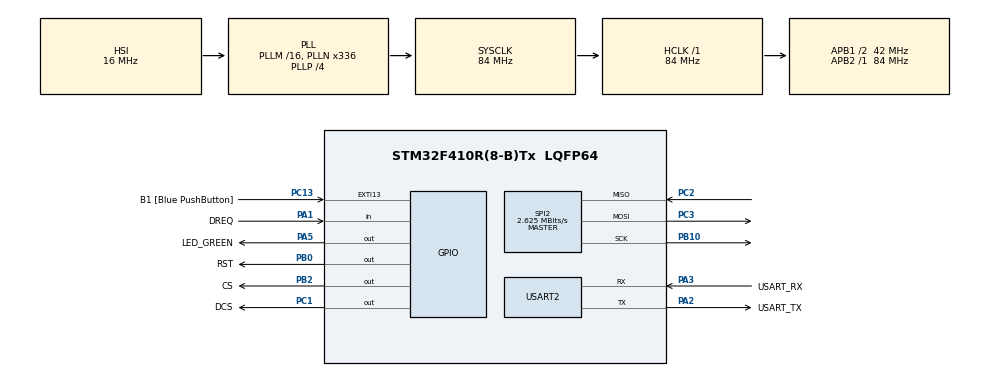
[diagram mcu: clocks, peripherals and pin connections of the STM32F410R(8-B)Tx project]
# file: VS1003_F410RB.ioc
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Mcu.Family=STM32F4
Mcu.Name=STM32F410R(8-B)Tx
Mcu.Package=LQFP64
NVIC.PriorityGroup=NVIC_PRIORITYGROUP_0
PA1.GPIO_Label=DREQ
PA1.Signal=GPIO_Input
PA13.GPIO_Label=TMS
PA13.Mode=Serial_Wire
PA13.Signal=SYS_JTMS-SWDIO
PA14.GPIO_Label=TCK
PA14.Mode=Serial_Wire
PA14.Signal=SYS_JTCK-SWCLK
PA2.GPIO_Label=USART_TX
PA2.Mode=Asynchronous
PA2.Signal=USART2_TX
PA3.GPIO_Label=USART_RX
PA3.Mode=Asynchronous
PA3.Signal=USART2_RX
PA5.GPIO_Label=LED_GREEN
PA5.Signal=GPIO_Output
PB0.GPIO_Label=RST
PB0.Signal=GPIO_Output
PB10.Mode=Full_Duplex_Master
PB10.Signal=SPI2_SCK
PB2.GPIO_Label=CS
PB2.Signal=GPIO_Output
PB3.GPIO_Label=SWO
PB3.Signal=SYS_JTDO-SWO
PC1.GPIO_Label=DCS
PC1.Signal=GPIO_Output
PC13-ANTI_TAMP.GPIO_Label=B1 [Blue PushButton]
PC13-ANTI_TAMP.GPIO_ModeDefaultEXTI=GPIO_MODE_IT_FALLING
PC13-ANTI_TAMP.Signal=GPXTI13
PC14-OSC32_IN.Mode=LSE-External-Oscillator
PC14-OSC32_IN.Signal=RCC_OSC32_IN
PC15-OSC32_OUT.Mode=LSE-External-Oscillator
PC15-OSC32_OUT.Signal=RCC_OSC32_OUT
PC2.Mode=Full_Duplex_Master
PC2.Signal=SPI2_MISO
PC3.Mode=Full_Duplex_Master
PC3.Signal=SPI2_MOSI
PH0\ -\ OSC_IN.Mode=HSE-External-Clock-Source
PH0\ -\ OSC_IN.Signal=RCC_OSC_IN
PH1\ -\ OSC_OUT.Mode=HSE-External-Clock-Source
PH1\ -\ OSC_OUT.Signal=RCC_OSC_OUT
ProjectManager.HeapSize=0x200
ProjectManager.StackSize=0x400
ProjectManager.TargetToolchain=STM32CubeIDE
RCC.48MHZClocksFreq_Value=84000000
RCC.AHBFreq_Value=84000000
RCC.APB1CLKDivider=RCC_HCLK_DIV2
RCC.APB1Freq_Value=42000000
RCC.APB1TimFreq_Value=84000000
RCC.APB2Freq_Value=84000000
RCC.APB2TimFreq_Value=84000000
RCC.CortexFreq_Value=84000000
RCC.FLatency-AdvancedSettings=FLASH_LATENCY_2
RCC.HCLKFreq_Value=84000000
RCC.HSE_VALUE=8000000
RCC.HSI_VALUE=16000000
RCC.PLLN=336
RCC.PLLP=RCC_PLLP_DIV4
RCC.SYSCLKFreq_VALUE=84000000
RCC.SYSCLKSource=RCC_SYSCLKSOURCE_PLLCLK
RCC.VCOOutputFreq_Value=336000000
SPI2.BaudRatePrescaler=SPI_BAUDRATEPRESCALER_16
SPI2.CalculateBaudRate=2.625 MBits/s
SPI2.Direction=SPI_DIRECTION_2LINES
SPI2.Mode=SPI_MODE_MASTER
SPI2.VirtualType=VM_MASTER
USART2.VirtualMode=VM_ASYNC
board=NUCLEO-F410RB

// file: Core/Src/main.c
/* USER CODE BEGIN Header */
/**
 ******************************************************************************
 * @file           : main.c
 * @brief          : Main program body
 ******************************************************************************
 * @attention
 *
 * Copyright (c) 2024 STMicroelectronics.
 * All rights reserved.
 *
 * This software is licensed under terms that can be found in the LICENSE file
 * in the root directory of this software component.
 * If no LICENSE file comes with this software, it is provided AS-IS.
 *
 ******************************************************************************
 */
/* USER CODE END Header */
#include <vs1003.h>
#include "main.h"

SPI_HandleTypeDef hspi2;

UART_HandleTypeDef huart2;

void SystemClock_Config(void);
static void MX_GPIO_Init(void);
static void MX_USART2_UART_Init(void);
static void MX_SPI2_Init(void);

/* USER CODE BEGIN 0 */
unsigned char HelloMP3[] = { 0xFF, 0xF2, 0x40, 0xC0, 0x19, 0xB7, 0x00, 0x14,
		0x02, 0xE6, 0x5C, /* ..@.......\ */
		0x01, 0x92, 0x68, 0x01, 0xF1, 0x5E, 0x03, 0x08, 0xF0, 0x24, 0x80, /* ..h..^...$. */
		0x05, 0x9E, 0x20, 0xC6, 0xFC, 0x12, 0x32, 0x5C, 0xBF, 0xF9, 0xB9, /* .. ...2\... */
		0x20, 0x4A, 0x7F, 0x85, 0xEC, 0x4C, 0xCD, 0xC7, 0x27, 0xFE, 0x5C, /*  J...L..'.\ */
		0x34, 0x25, 0xCB, 0xE6, 0xFF, 0xFF, 0x8E, 0x42, 0xE1, 0xA0, 0x5E, /* 4%.....B..^ */
		0xCA, 0x6E, 0x30, 0x9F, 0xFF, 0xF8, 0xC2, 0x12, 0x84, 0xB9, 0x7C, /* .n0.......| */
		0xDC, 0x61, 0x09, 0x4A, 0x7F, 0xFF, 0xFF, 0xF9, 0x7D, 0x32, 0x51, /* .a.J....}2Q */
		0x09, 0x7C, 0xE1, 0xA5, 0x6E, 0xB4, 0xFF, 0xFF, 0xFF, 0xFF, 0xD3, /* .|..n...... */
		0x34, 0x41, 0x91, 0xF0, 0x11, 0x8F, 0x00, 0x0F, 0x81, 0x9C, 0x10, /* 4A......... */
		0xEE, 0x59, 0xCE, 0x56, 0x67, 0xFF, 0xF2, 0x42, 0xC0, 0xEC, 0x53, /* .Y.Vg..B..S */
		0x09, 0x15, 0xF9, 0xAA, 0xA8, 0x0D, 0xD9, 0x40, 0x00, 0xCA, 0x34, /* .......@..4 */
		0x53, 0xD9, 0x18, 0xAB, 0x7D, 0xF7, 0x89, 0x3F, 0x11, 0x38, 0x94, /* S...}..?.8. */
		0x82, 0x59, 0x93, 0x20, 0x6A, 0x0C, 0xEE, 0x8E, 0x58, 0xFA, 0x38, /* .Y. j...X.8 */
		0x82, 0xCA, 0xF0, 0x58, 0xBB, 0xDA, 0x0C, 0x50, 0x56, 0x1F, 0xBB, /* ...X...PV.. */
		0x18, 0x5D, 0x8B, 0x9F, 0xDA, 0x71, 0x4F, 0xFF, 0xBD, 0xFE, 0xEF, /* .]...qO.... */
		0x69, 0x36, 0x86, 0x3C, 0x50, 0xBB, 0x0A, 0x07, 0x89, 0x54, 0xF0, /* i6.<P....T. */
		0x88, 0x9F, 0x90, 0x95, 0x30, 0x94, 0x2E, 0x7E, 0xF0, 0x64, 0x96, /* ....0..~.d. */
		0x79, 0x08, 0x3E, 0x20, 0x97, 0x28, 0x34, 0x9C, 0x09, 0x7F, 0xD2, /* y.> .(4.... */
		0xC0, 0x01, 0x75, 0xF8, 0x05, 0x6B, 0x5F, 0x41, 0x17, 0x0B, 0xE7, /* ..u..k_A... */
		0xFF, 0xF2, 0x40, 0xC0, 0x61, 0xE5, 0x0B, 0x16, 0x09, 0xC6, 0xC5, /* ..@.a...... */
		0x74, 0x7B, 0xCC, 0x94, 0x7A, 0xF7, 0x80, 0x76, 0xB2, 0xD2, 0xF8, /* t{..z..v... */
		0x39, 0x06, 0x38, 0xFD, 0x71, 0xC5, 0xDE, 0x3A, 0x38, 0xBF, 0xD5, /* 9.8.q..:8.. */
		0xF7, 0x12, 0x37, 0xCB, 0xF5, 0x63, 0x0C, 0x9B, 0xCE, 0x77, 0x25, /* ..7..c...w% */
		0xED, 0xFB, 0x3D, 0x6B, 0x35, 0xF9, 0x6D, 0xD7, 0xF9, 0x2C, 0xD1, /* ..=k5.m..,. */
		0x97, 0x15, 0x87, 0x93, 0xA4, 0x49, 0x4A, 0x18, 0x16, 0x07, 0xA1, /* .....IJ.... */
		0x60, 0xF7, 0x52, 0x94, 0xDB, 0x02, 0x16, 0x70, 0xB2, 0xD8, 0x80, /* `.R....p... */
		0x30, 0xC2, 0x94, 0x40, 0x81, 0x74, 0x5A, 0x19, 0x7A, 0x80, 0x60, /* 0..@.tZ.z.` */
		0x41, 0x21, 0x46, 0x95, 0xD5, 0xC4, 0x40, 0xD2, 0x01, 0xC0, 0x01, /* A!F...@.... */
		0xDA, 0xD9, 0xA0, 0xB1, 0x01, 0xFF, 0xF2, 0x42, 0xC0, 0x82, 0x10, /* .......B... */
		0x0B, 0x12, 0xF9, 0x9E, 0xC9, 0x7E, 0x7A, 0xC6, 0x95, 0x55, 0x09, /* .....~z..U. */
		0x8B, 0x19, 0x5E, 0x8B, 0x26, 0xCA, 0xEB, 0x68, 0x8A, 0x05, 0x8F, /* ..^.&..h... */
		0x36, 0xA5, 0xA5, 0x03, 0xB8, 0x9C, 0xED, 0x24, 0x51, 0x59, 0x90, /* 6......$QY. */
		0xF6, 0xC5, 0x7D, 0xB5, 0xAD, 0xAF, 0xF6, 0x3B, 0x18, 0xEF, 0x3F, /* ..}....;..? */
		0xFF, 0xFF, 0x4E, 0xDE, 0x16, 0x66, 0x0B, 0xAA, 0x33, 0x23, 0xDD, /* ..N..f..3#. */
		0x9C, 0x4E, 0x6E, 0x55, 0x22, 0x9D, 0xA2, 0x40, 0xA6, 0x36, 0x31, /* .NnU"..@.61 */
		0x69, 0xA5, 0xE1, 0xD9, 0x7F, 0xF7, 0xC6, 0xCC, 0x48, 0x00, 0x0E, /* i.......H.. */
		0x90, 0x16, 0x00, 0x0F, 0xDE, 0x6E, 0x80, 0x11, 0x0C, 0x9A, 0x4F, /* .....n....O */
		0x56, 0xDB, 0x88, 0xD3, 0xB2, 0x1C, 0x00, 0xE0, 0x2E, 0x3E, 0xAC, /* V........>. */
		0xFF, 0xF2, 0x40, 0xC0, 0x1C, 0xE5, 0x19, 0x13, 0x31, 0x4E, 0xCD, /* ..@.....1N. */
		0x9E, 0xC3, 0x06, 0x71, 0x03, 0x85, 0xE5, 0xB5, 0x6D, 0x88, 0x50, /* ...q....m.P */
		0x8E, 0x0E, 0x17, 0x3B, 0x19, 0xFB, 0x4E, 0x3B, 0x99, 0xEF, 0x4C, /* ...;..N;..L */
		0x9E, 0xF7, 0x7B, 0x31, 0x7C, 0x3C, 0x5F, 0xFF, 0xF4, 0xF8, 0xE3, /* ..{1|<_.... */
		0x92, 0x42, 0x07, 0x8E, 0x83, 0x8E, 0x0F, 0x05, 0x08, 0x91, 0xA3, /* .B......... */
		0x16, 0xE2, 0xDF, 0xB7, 0x62, 0x60, 0x48, 0x31, 0x3C, 0xFF, 0xD4, /* ....b`H1<.. */
		0x9E, 0x0C, 0x68, 0x00, 0x77, 0x54, 0xE3, 0x1E, 0x05, 0xC5, 0xF8, /* ..h.wT..... */
		0xEA, 0x8D, 0x82, 0x9D, 0x08, 0xA9, 0x06, 0x8D, 0x1E, 0x5D, 0x7C, /* .........]| */
		0x7F, 0x08, 0xC0, 0x50, 0x45, 0x42, 0xD0, 0x36, 0xF8, 0xB2, 0x4D, /* ...PEB.6..M */
		0x53, 0x0C, 0x80, 0x3B, 0x4D, 0xFF, 0xF2, 0x42, 0xC0, 0x2F, 0x3C, /* S..;M..B./< */
		0x25, 0x19, 0x29, 0xFE, 0xBC, 0x2E, 0xC4, 0xD0, 0x99, 0x4C, 0x48, /* %.)......LH */
		0xB0, 0x9C, 0x49, 0xD2, 0x1A, 0x2D, 0x02, 0xC2, 0x79, 0x69, 0x16, /* ..I..-..yi. */
		0x92, 0xA8, 0xC5, 0xAB, 0x45, 0x5A, 0x68, 0xE8, 0x75, 0x57, 0xCD, /* ....EZh.uW. */
		0xF1, 0xB9, 0xAA, 0x13, 0x88, 0xE4, 0x87, 0x42, 0x15, 0xB3, 0x58, /* .......B..X */
		0xF5, 0xA3, 0x46, 0xB1, 0xCF, 0xD3, 0x59, 0x7E, 0xBA, 0xB5, 0xA7, /* ..F...Y~... */
		0x6B, 0x0B, 0x17, 0x57, 0x6B, 0x5C, 0x4A, 0xCD, 0x53, 0x76, 0x2A, /* k..Wk\J.Sv* */
		0x1D, 0x28, 0xC5, 0x1C, 0x76, 0x5C, 0xDD, 0x0A, 0x00, 0x4B, 0xC0, /* .(..v\...K. */
		0x1B, 0xCA, 0xA8, 0xE9, 0x81, 0x5B, 0xA6, 0xDC, 0xA4, 0x59, 0x13, /* .....[...Y. */
		0xFC, 0xBA, 0x8F, 0x98, 0x79, 0x44, 0x25, 0xC9, 0x35, 0x38, 0xCA, /* ....yD%.58. */
		0xFF, 0xF2, 0x40, 0xC0, 0xB9, 0x7D, 0x1A, 0x13, 0x79, 0x6A, 0xC8, /* ..@..}..yj. */
		0x3E, 0xC4, 0x46, 0x94, 0x8D, 0x3C, 0x67, 0x85, 0xB1, 0xA8, 0x89, /* >.F..<g.... */
		0xC0, 0xF2, 0xE6, 0x2F, 0x9D, 0x7C, 0xC9, 0xB4, 0xBE, 0xCF, 0xE1, /* .../.|..... */
		0x7D, 0xFE, 0x1F, 0x03, 0x00, 0x12, 0x84, 0x72, 0x8C, 0xE7, 0xD8, /* }......r... */
		0x5E, 0xC9, 0xA9, 0x01, 0xBA, 0x9B, 0xC4, 0x10, 0x5C, 0x70, 0x2E, /* ^.......\p. */
		0x6C, 0x48, 0xE7, 0x8C, 0x15, 0x0B, 0x06, 0x01, 0xE5, 0xFF, 0xFF, /* lH......... */
		0xD4, 0x0D, 0x00, 0x0F, 0xCE, 0x58, 0x95, 0x61, 0xA8, 0x9E, 0x7B, /* .....X.a..{ */
		0x19, 0x98, 0xB0, 0xF0, 0xC6, 0x72, 0x82, 0xD5, 0x27, 0x06, 0x47, /* .....r..'.G */
		0x41, 0x22, 0x0F, 0x65, 0x93, 0xC9, 0x8A, 0x09, 0x19, 0x48, 0x1B, /* A".e.....H. */
		0xBD, 0xD6, 0x64, 0x1A, 0xAC, 0xFF, 0xF2, 0x42, 0xC0, 0xF1, 0x11, /* ..d....B... */
		0x25, 0x14, 0x22, 0x06, 0xBC, 0x0E, 0xD4, 0x4E, 0x99, 0x90, 0xA8, /* %."....N... */
		0xD8, 0xB7, 0xAD, 0x5D, 0x3E, 0xAF, 0x6E, 0xBE, 0x66, 0x83, 0xA4, /* ...]>.n.f.. */
		0xE3, 0xC2, 0xE0, 0x29, 0x43, 0x87, 0x5F, 0x4F, 0x27, 0x9C, 0x2C, /* ...)C._O'., */
		0xD0, 0x91, 0xF3, 0x87, 0x9B, 0x54, 0xED, 0xD1, 0xB4, 0xF3, 0x39, /* .....T....9 */
		0x87, 0x22, 0x06, 0x86, 0x0D, 0x71, 0xE4, 0x6F, 0x2A, 0x08, 0x04, /* ."...q.o*.. */
		0xC0, 0x03, 0x2A, 0xB1, 0xE2, 0x05, 0x4D, 0x64, 0xA1, 0x9C, 0xA6, /* ..*...Md... */
		0x0D, 0x41, 0xA6, 0xF2, 0x7A, 0xC1, 0x30, 0xC3, 0x38, 0x26, 0x09, /* .A..z.0.8&. */
		0x50, 0x08, 0xC4, 0xF6, 0x30, 0x0C, 0xA6, 0xA9, 0x17, 0x00, 0x13, /* P...0...... */
		0x0C, 0xDC, 0xC4, 0x2F, 0x28, 0xEB, 0x3F, 0xCD, 0x7A, 0x3D, 0x2F, /* .../(.?.z=/ */
		0xFF, 0xF2, 0x40, 0xC0, 0x18, 0x6F, 0x2E, 0x13, 0xA1, 0xF2, 0xBC, /* ..@..o..... */
		0x36, 0xCB, 0x4E, 0x99, 0x6E, 0xFC, 0xEE, 0xC5, 0xF0, 0xA0, 0xB7, /* 6.N.n...... */
		0x92, 0xD4, 0xEE, 0x79, 0x7C, 0x50, 0x5D, 0xE5, 0x04, 0x94, 0xA9, /* ...y|P].... */
		0x76, 0xCF, 0x6C, 0x70, 0xDD, 0x0D, 0xD4, 0xEE, 0xED, 0x98, 0xE8, /* v.lp....... */
		0xC8, 0x35, 0x36, 0x7A, 0x0C, 0x05, 0x80, 0x03, 0xBC, 0xBE, 0x91, /* .56z....... */
		0x00, 0x7C, 0xAE, 0x65, 0xB8, 0x91, 0xA3, 0x33, 0xBA, 0x68, 0x60, /* .|.e...3.h` */
		0xD4, 0x1A, 0x66, 0xF8, 0x43, 0xA0, 0x20, 0x89, 0xE7, 0x80, 0xD8, /* ..f.C. .... */
		0x1E, 0x4F, 0xA0, 0x04, 0x60, 0x06, 0x0A, 0xA4, 0x91, 0x24, 0xFA, /* .O..`....$. */
		0x9F, 0x57, 0x53, 0xF4, 0x7A, 0xDB, 0x5F, 0x56, 0xE3, 0x6E, 0x0B, /* .WS.z._V.n. */
		0x8B, 0x3A, 0x1C, 0xF9, 0x5E, 0xFF, 0xF2, 0x42, 0xC0, 0xB1, 0x00, /* .:..^..B... */
		0x38, 0x14, 0x09, 0xEE, 0xB4, 0x36, 0xD3, 0x4E, 0x99, 0xA4, 0x78, /* 8....6.N..x */
		0x94, 0x73, 0xC4, 0x66, 0x30, 0xF5, 0xEA, 0xDB, 0xBA, 0x67, 0x67, /* .s.f0....gg */
		0x95, 0x6B, 0xAB, 0x68, 0x5D, 0x08, 0xA1, 0x39, 0x56, 0xAB, 0x1E, /* .k.h]..9V.. */
		0xD5, 0x03, 0xE8, 0x01, 0x70, 0x00, 0xB3, 0x93, 0x33, 0x19, 0x8C, /* ....p...3.. */
		0x61, 0x8F, 0xBB, 0x5D, 0x24, 0x12, 0x63, 0xD3, 0x4B, 0x5D, 0x91, /* a..]$.c.K]. */
		0x08, 0x43, 0x22, 0x56, 0x1A, 0xC5, 0x10, 0x21, 0x84, 0xA8, 0xEA, /* .C"V...!... */
		0x80, 0xBF, 0x16, 0x8E, 0x3D, 0x46, 0x18, 0x9C, 0x6E, 0x9A, 0x91, /* ....=F..n.. */
		0xE6, 0xC9, 0x6F, 0xD2, 0x7D, 0x27, 0xD7, 0xE9, 0x6B, 0xFF, 0x0A, /* ..o.}'..k.. */
		0x03, 0x43, 0x89, 0xD5, 0xBF, 0x52, 0x97, 0x0A, 0x25, 0x95, 0x0D, /* .C...R..%.. */
		0xFF, 0xF2, 0x40, 0xC0, 0xF5, 0xC3, 0x41, 0x13, 0x81, 0xEE, 0xA8, /* ..@...A.... */
		0x5E, 0xD3, 0x44, 0x98, 0xFC, 0xCF, 0x97, 0xF9, 0x58, 0xB5, 0x33, /* ^.D.....X.3 */
		0xB1, 0x85, 0x47, 0x86, 0xD7, 0x98, 0x01, 0x3B, 0xA3, 0x4F, 0x7E, /* ..G....;.O~ */
		0x04, 0xA6, 0xC3, 0x39, 0x21, 0x70, 0x27, 0x62, 0xB5, 0x18, 0x10, /* ...9!p'b... */
		0x09, 0x99, 0x00, 0x8B, 0x7E, 0xF2, 0xBF, 0x52, 0x18, 0x26, 0x30, /* ....~..R.&0 */
		0x1C, 0xB0, 0x01, 0x49, 0x30, 0xE0, 0xC3, 0x11, 0x46, 0x05, 0xCC, /* ...I0...F.. */
		0x49, 0x14, 0x28, 0xB2, 0xED, 0x4B, 0x57, 0x5A, 0x2F, 0xB7, 0x46, /* I.(..KWZ/.F */
		0x63, 0x34, 0xD2, 0xDA, 0x9F, 0x56, 0x32, 0xB7, 0xA2, 0x25, 0xFF, /* c4...V2..%. */
		0x94, 0x28, 0x33, 0x7F, 0x3B, 0xC4, 0x50, 0xEC, 0xB1, 0xE2, 0x26, /* .(3.;.P...& */
		0xA1, 0xB7, 0x07, 0x7F, 0xFB, 0xFF, 0xF2, 0x42, 0xC0, 0x67, 0x6A, /* .......B.gj */
		0x4C, 0x13, 0xF9, 0x6A, 0x90, 0x7E, 0xDB, 0x44, 0x94, 0x3F, 0xFF, /* L..j.~.D.?. */
		0x14, 0xD6, 0x2A, 0xFF, 0xFF, 0xC1, 0x34, 0x8C, 0x48, 0x22, 0x00, /* ..*...4.H". */
		0x06, 0x8F, 0x21, 0xFD, 0x64, 0x60, 0x04, 0x92, 0x42, 0xEA, 0x74, /* ..!.d`..B.t */
		0x32, 0x37, 0xAA, 0x5A, 0x9F, 0x67, 0x01, 0x8B, 0x3F, 0x37, 0x31, /* 27.Z.g..?71 */
		0xDD, 0x06, 0x3C, 0x01, 0x34, 0x30, 0xE0, 0x5C, 0x78, 0x78, 0xCB, /* ..<.40.\xx. */
		0xD6, 0xF1, 0x31, 0x8A, 0x69, 0x61, 0x93, 0x92, 0x42, 0xCE, 0x4B, /* ..1.ia..B.K */
		0xC5, 0x02, 0x4E, 0x73, 0xC6, 0x24, 0x30, 0xCD, 0x08, 0x66, 0xC6, /* ..Ns.$0..f. */
		0x35, 0xAB, 0xA2, 0x3D, 0x2F, 0xB3, 0xBD, 0x34, 0x87, 0x13, 0xEE, /* 5..=/..4... */
		0x71, 0x45, 0x68, 0xFA, 0xEA, 0x05, 0x84, 0x41, 0x36, 0x4C, 0x9A, /* qEh....A6L. */
		0xFF, 0xF2, 0x40, 0xC0, 0xC9, 0x92, 0x56, 0x13, 0xD0, 0x6E, 0x70, /* ..@...V..np */
		0x54, 0xD3, 0xCC, 0x28, 0x06, 0xD7, 0x0E, 0xA4, 0x1D, 0x9C, 0x9D, /* T..(....... */
		0xD9, 0xA9, 0x88, 0x7B, 0xB5, 0xA3, 0x56, 0xB7, 0x4B, 0x4B, 0x5A, /* ...{..V.KKZ */
		0x9B, 0x2C, 0xA9, 0xAD, 0x6F, 0x99, 0x6C, 0xC0, 0x4C, 0x14, 0x14, /* .,..o.l.L.. */
		0xEF, 0xB4, 0x20, 0x91, 0x5F, 0xBC, 0x81, 0x41, 0x41, 0x5D, 0xD4, /* .. ._..AA]. */
		0x20, 0xBD, 0x05, 0x1A, 0x6F, 0xE2, 0x68, 0x56, 0x41, 0x41, 0x57, /*  ...o.hVAAW */
		0xF9, 0xBF, 0x89, 0x82, 0x8E, 0xC7, 0x8F, 0x0A, 0x0A, 0x09, 0x37, /* ..........7 */
		0xF1, 0x05, 0x0A, 0x0A, 0x0A, 0x0A, 0x09, 0x05, 0x37, 0xFF, 0x10, /* ........7.. */
		0x50, 0x50, 0x53, 0x65, 0xFF, 0xFF, 0xFD, 0x75, 0xDF, 0xFF, 0xFF, /* PPSe...u... */
		0x68, 0x4F, 0xFF, 0x84, 0x70, 0xFF, 0xF2, 0x42, 0xC0, 0x27, 0x50, /* hO..p..B.'P */
		0x5F, 0x17, 0xE8, 0x82, 0x3C, 0x11, 0x58, 0x18, 0x01, 0x55, 0x48, /* _...<.X..UH */
		0xBC, 0x52, 0xFC, 0x4A, 0x4C, 0x3C, 0xD5, 0xF6, 0x11, 0x2D, 0xBF, /* .R.JL<...-. */
		0xEA, 0x03, 0x5C, 0x57, 0x29, 0xBF, 0xC3, 0x75, 0x1C, 0xE6, 0xDD, /* ..\W)..u... */
		0xBF, 0xED, 0xEF, 0xD0, 0x98, 0x77, 0x71, 0x95, 0x73, 0xFF, 0xED, /* .....wq.s.. */
		0x54, 0xBE, 0xD5, 0xEE, 0xAE, 0xC2, 0xD5, 0x0B, 0xFF, 0xF1, 0x97, /* T.......... */
		0x8A, 0xE4, 0x42, 0x09, 0x99, 0xB1, 0xEA, 0x94, 0xDC, 0x78, 0xB5, /* ..B......x. */
		0x34, 0x0F, 0xF1, 0x8F, 0xFC, 0x15, 0xF6, 0xFA, 0xB1, 0x47, 0xA9, /* 4........G. */
		0x6C, 0x67, 0x43, 0x8B, 0xF2, 0x76, 0x22, 0xED, 0xDA, 0x85, 0xBA, /* lgC..v".... */
		0x2F, 0xC7, 0xF9, 0xCF, 0xFC, 0xDB, 0x46, 0x2E, 0x50, 0x0A, 0x84, /* /.....F.P.. */
		0xFF, 0xF2, 0x40, 0xC0, 0xC6, 0x4A, 0x59, 0x28, 0x2B, 0x19, 0xE0, /* ..@..JY(+.. */
		0x01, 0x89, 0x78, 0x00, 0x52, 0x85, 0x3C, 0x8E, 0x54, 0x9A, 0x48, /* ..x.R.<.T.H */
		0x5A, 0x72, 0x32, 0x94, 0xBF, 0x43, 0x4F, 0x24, 0x53, 0x4B, 0xEC, /* Zr2..CO$SK. */
		0x4B, 0x99, 0x0E, 0x66, 0x1F, 0xFF, 0xCE, 0x7F, 0xFF, 0x3F, 0x10, /* K..f.....?. */
		0xAE, 0x82, 0x62, 0x71, 0x34, 0x18, 0x59, 0x9B, 0x51, 0xC7, 0x59, /* ..bq4.Y.Q.Y */
		0xCE, 0xEE, 0xA5, 0xFE, 0x02, 0xBB, 0x30, 0x91, 0x49, 0xD5, 0x4B, /* ......0.I.K */
		0xF3, 0xDC, 0x9A, 0xA9, 0x57, 0x8E, 0x72, 0x10, 0xC0, 0x5D, 0x60, /* ....W.r..]` */
		0x67, 0xFC, 0x7D, 0xD6, 0xBA, 0xDD, 0xB3, 0x8B, 0x5A, 0x0A, 0x4C, /* g.}.....Z.L */
		0x41, 0x4D, 0x45, 0x33, 0x2E, 0x39, 0x33, 0xAA, 0xAA, 0xAA, 0xAA, /* AME3.93.... */
		0xAA, 0xAA, 0xAA, 0xAA, 0xAA, 0x54, 0x41, 0x47, 0x48, 0x65, 0x6C, /* .....TAGHel */
		0x6C, 0x6F, 0x20, 0x20, 0x20, 0x20, 0x20, 0x20, 0x20, 0x20, 0x20, /* lo          */
		0x20, 0x20, 0x20, 0x20, 0x20, 0x20, 0x20, 0x20, 0x20, 0x20, 0x20, /*             */
		0x20, 0x20, 0x20, 0x20, 0x20, 0x50, 0x61, 0x6E, 0x75, 0x2D, 0x4B, /*      Panu-K */
		0x72, 0x69, 0x73, 0x74, 0x69, 0x61, 0x6E, 0x20, 0x50, 0x6F, 0x69, /* ristian Poi */
		0x6B, 0x73, 0x61, 0x6C, 0x6F, 0x20, 0x20, 0x20, 0x20, 0x20, 0x20, /* ksalo       */
		0x20, 0x20, 0x56, 0x53, 0x44, 0x53, 0x50, 0x20, 0x54, 0x65, 0x73, /*   VSDSP Tes */
		0x74, 0x69, 0x6E, 0x67, 0x20, 0x20, 0x20, 0x20, 0x20, 0x20, 0x20, /* ting        */
		0x20, 0x20, 0x20, 0x20, 0x20, 0x20, 0x20, 0x20, 0x20, 0x20, 0x20, /*             */
		0x20, 0x20, 0x20, 0x4D, 0x50, 0x33, 0x20, 0x48, 0x65, 0x6C, 0x6C, /*    MP3 Hell */
		0x6F, 0x2C, 0x20, 0x57, 0x6F, 0x72, 0x6C, 0x64, 0x21, 0x20, 0x20, /* o, World!   */
		0x20, 0x20, 0x20, 0x20, 0x20, 0x20, 0x20, 0x20, 0x20, 0x20, 0x20, /*             */
		0x00, /* . */
};
unsigned char bell[] = { 0x49, 0x44, 0x33, 0x04, 0x00, 0x00, 0x00, 0x00, 0x00,
		0x23, 0x54, 0x53, 0x53, 0x45, 0x00, 0x00, 0x00, 0x0F, 0x00, 0x00, 0x03,
		0x4C, 0x61, 0x76, 0x66, 0x36, 0x30, 0x2E, 0x31, 0x35, 0x2E, 0x31, 0x30,
		0x30, 0x00, 0x00, 0x00, 0x00, 0x00, 0x00, 0x00, 0x00, 0x00, 0x00, 0x00,
		0xFF, 0xFB, 0x50, 0x00, 0x00, 0x00, 0x00, 0x00, 0x00, 0x00, 0x00, 0x00,
		0x00, 0x00, 0x00, 0x00, 0x00, 0x00, 0x00, 0x00, 0x00, 0x00, 0x00, 0x00,
		0x00, 0x00, 0x00, 0x00, 0x00, 0x00, 0x00, 0x00, 0x00, 0x00, 0x00, 0x00,
		0x49, 0x6E, 0x66, 0x6F, 0x00, 0x00, 0x00, 0x0F, 0x00, 0x00, 0x00, 0x47,
		0x00, 0x00, 0x1D, 0xCB, 0x00, 0x0A, 0x0D, 0x11, 0x11, 0x15, 0x18, 0x18,
		0x1C, 0x1F, 0x23, 0x23, 0x26, 0x2A, 0x2A, 0x2D, 0x31, 0x34, 0x34, 0x38,
		0x3B, 0x3B, 0x3F, 0x42, 0x46, 0x46, 0x49, 0x4D, 0x4D, 0x50, 0x54, 0x57,
		0x57, 0x5B, 0x5E, 0x5E, 0x62, 0x65, 0x65, 0x69, 0x6C, 0x70, 0x70, 0x73,
		0x77, 0x77, 0x7A, 0x7E, 0x81, 0x81, 0x85, 0x88, 0x88, 0x8C, 0x8F, 0x93,
		0x93, 0x96, 0x9A, 0x9A, 0x9D, 0xA1, 0xA4, 0xA4, 0xA8, 0xAB, 0xAB, 0xAF,
		0xB2, 0xB2, 0xB6, 0xB9, 0xBD, 0xBD, 0xC0, 0xC4, 0xC4, 0xC7, 0xCB, 0xCE,
		0xCE, 0xD2, 0xD5, 0xD5, 0xD9, 0xDC, 0xE0, 0xE0, 0xE3, 0xE7, 0xE7, 0xEA,
		0xEE, 0xF1, 0xF1, 0xF5, 0xF8, 0xF8, 0xFC, 0xFF, 0x00, 0x00, 0x00, 0x00,
		0x4C, 0x61, 0x76, 0x63, 0x36, 0x30, 0x2E, 0x33, 0x30, 0x00, 0x00, 0x00,
		0x00, 0x00, 0x00, 0x00, 0x00, 0x00, 0x00, 0x00, 0x00, 0x24, 0x02, 0x40,
		0x00, 0x00, 0x00, 0x00, 0x00, 0x00, 0x1D, 0xCB, 0x4A, 0x53, 0xAC, 0xDB,
		0x00, 0x00, 0x00, 0x00, 0x00, 0x00, 0x00, 0x00, 0x00, 0x00, 0x00, 0x00,
		0x00, 0x00, 0x00, 0x00, 0xFF, 0xFB, 0x10, 0x64, 0x00, 0x0F, 0xF0, 0x78,
		0x00, 0x3A, 0x00, 0x23, 0x10, 0x00, 0x0E, 0x60, 0x07, 0x50, 0x00, 0x00,
		0x00, 0x01, 0x74, 0x00, 0xFA, 0x00, 0x0C, 0x60, 0x00, 0x37, 0x80, 0x5F,
		0x00, 0x10, 0x8C, 0x00, 0xEA, 0x0C, 0xD4, 0x18, 0xF9, 0x43, 0x8A, 0x73,
		0x0E, 0x65, 0xDF, 0xFE, 0x48, 0x3F, 0x90, 0xEB, 0x7F, 0xC9, 0xE7, 0xC9,
		0xC3, 0xEB, 0x38, 0xB7, 0xFF, 0xE5, 0x01, 0x07, 0x43, 0xFD, 0x36, 0x84,
		0x11, 0xEC, 0xA0, 0xCE, 0x69, 0xFF, 0xFF, 0x9A, 0x15, 0x75, 0xDA, 0xC6,
		0xD2, 0xC6, 0xAA, 0xD7, 0x4A, 0x73, 0x35, 0xBB, 0xFF, 0x38, 0x2E, 0xBA,
		0xBB, 0x7C, 0xDB, 0xDF, 0x7B, 0x51, 0x6F, 0xFF, 0x55, 0x6B, 0x2C, 0xA6,
		0xFF, 0xFB, 0x12, 0x64, 0x06, 0x8F, 0xF0, 0x64, 0x00, 0x3E, 0x80, 0x20,
		0x00, 0x00, 0x0A, 0xC0, 0x07, 0xD0, 0x04, 0x00, 0x00, 0x01, 0xD8, 0x00,
		0xF6, 0x00, 0x84, 0x49, 0x40, 0x31, 0x00, 0x5E, 0xC0, 0x00, 0x88, 0x00,
		0xBE, 0xAF, 0x5C, 0xE3, 0xD9, 0x73, 0x76, 0x7F, 0xF5, 0x7A, 0x91, 0x5E,
		0x92, 0x8B, 0x7D, 0xBD, 0xE0, 0x06, 0x18, 0x7F, 0xFF, 0xCC, 0x20, 0x48,
		0x11, 0x62, 0x1F, 0x6D, 0x55, 0xDF, 0x2B, 0x62, 0x7F, 0xFF, 0xBC, 0x7A,
		0xE4, 0x2A, 0x05, 0xF8, 0x17, 0x02, 0x11, 0x1C, 0x4B, 0x56, 0x70, 0x60,
		0x32, 0x22, 0x30, 0xF2, 0x7A, 0x61, 0x04, 0xD8, 0xC2, 0x08, 0x38, 0xF1,
		0xF1, 0xB5, 0xF4, 0xDA, 0xDF, 0xFF, 0xFF, 0xCA, 0x03, 0xFF, 0xFB, 0x10,
		0x64, 0x0F, 0x8F, 0xF0, 0xAC, 0x0C, 0x47, 0x01, 0xEC, 0x30, 0x2A, 0x09,
		0xE0, 0x57, 0xE0, 0x08, 0x40, 0x00, 0x04, 0xB0, 0x37, 0x10, 0x15, 0xB7,
		0x80, 0x20, 0x39, 0x00, 0xA0, 0x42, 0x86, 0x20, 0x00, 0x27, 0xCE, 0xF0,
		0x20, 0x23, 0x31, 0x81, 0x54, 0x98, 0x60, 0xC5, 0xDA, 0x2E, 0xD3, 0xFE,
		0x8F, 0x2D, 0x7B, 0x28, 0xEA, 0xE5, 0x71, 0x68, 0x16, 0x19, 0x83, 0x48,
		0x89, 0xF0, 0xB9, 0x17, 0x25, 0xA2, 0x7A, 0x2E, 0x2E, 0x11, 0xF4, 0x34,
		0x31, 0x04, 0x1C, 0x2C, 0xD2, 0x26, 0x8D, 0x98, 0x7D, 0x6C, 0xFF, 0xFF,
		0xF4, 0x55, 0xE7, 0x53, 0x68, 0xD4, 0x29, 0x21, 0xE4, 0x78, 0x4E, 0x29,
		0x9A, 0xED, 0x7F, 0xA4, 0xDD, 0xFF, 0xFB, 0x12, 0x64, 0x07, 0x80, 0x00,
		0xF2, 0x0C, 0xD7, 0x86, 0x60, 0xA0, 0x00, 0x0F, 0x21, 0x6A, 0xA0, 0xC5,
		0x08, 0x00, 0x02, 0x54, 0x29, 0x56, 0x1D, 0x41, 0x00, 0x00, 0x3E, 0x04,
		0x6A, 0x17, 0x96, 0x20, 0x04, 0xE4, 0x19, 0x43, 0x43, 0x40, 0xD0, 0x88,
		0x54, 0x2F, 0x12, 0x84, 0x1D, 0x83, 0xA0, 0x9A, 0x38, 0x33, 0x0F, 0xF0,
		0xEC, 0xA7, 0x2E, 0x58, 0xE5, 0xC0, 0x86, 0xCB, 0x86, 0xF9, 0x43, 0x47,
		0xA5, 0x90, 0xBF, 0xA0, 0x6E, 0x91, 0x05, 0x91, 0x0E, 0x72, 0x68, 0xA3,
		0x5F, 0x56, 0x22, 0xB3, 0x3F, 0xE8, 0x07, 0x80, 0x07, 0x39, 0x1C, 0x2C,
		0x0F, 0xA8, 0x79, 0x18, 0x5C, 0xD5, 0x4F, 0x37, 0x5A, 0xA5, 0x07, 0xE0,
		0x02, 0xB3, 0xFF, 0xFB, 0x10, 0x64, 0x02, 0x03, 0xF0, 0x78, 0x04, 0xD6,
		0xA8, 0x38, 0x10, 0x8C, 0x0D, 0x80, 0xBA, 0x38, 0x40, 0x02, 0x23, 0x02,
		0xAC, 0x4B, 0x4A, 0x01, 0x69, 0xA0, 0x80, 0x3C, 0x82, 0x62, 0x40, 0x0E,
		0xE8, 0x0C, 0x0D, 0xFC, 0x99, 0xE1, 0x42, 0xD6, 0x44, 0xB5, 0x3E, 0xFB,
		0x68, 0x00, 0x02, 0x92, 0x00, 0xCB, 0x25, 0x80, 0x8F, 0x1B, 0x48, 0x31,
		0x63, 0xB9, 0x21, 0xB1, 0x86, 0x06, 0x7D, 0x93, 0xBE, 0x77, 0x29, 0xCE,
		0x8A, 0xE7, 0xF2, 0xBE, 0x74, 0xB7, 0x95, 0x79, 0xEE, 0x74, 0xFF, 0x3A,
		0x58, 0x28, 0x4C, 0xA0, 0x28, 0x0F, 0xFD, 0xFF, 0x3C, 0xB0, 0x4C, 0xB0,
		0x4C, 0xE1, 0xC2, 0x03, 0xE0, 0x07, 0x35, 0x4E, 0xD2, 0x0D, 0xFF, 0xFB,
		0x12, 0x64, 0x03, 0x83, 0xF0, 0xA9, 0x0E, 0xD3, 0x2B, 0x49, 0x11, 0x18,
		0x0E, 0x81, 0x39, 0x70, 0x03, 0x71, 0x03, 0x02, 0x78, 0x1F, 0x6F, 0x00,
		0xB0, 0xC0, 0xA8, 0x34, 0x84, 0x28, 0x80, 0x2C, 0x98, 0x4C, 0xEC, 0x6A,
		0x44, 0x26, 0x34, 0x5C, 0x6C, 0x6E, 0x80, 0x5D, 0x46, 0xE0, 0xF4, 0xCA,
		0x41, 0xC9, 0xF6, 0x64, 0xFF, 0xE6, 0x4E, 0x4F, 0x08, 0xF1, 0x72, 0x10,
		0x9F, 0xE4, 0x2E, 0x15, 0xFF, 0xEC, 0x10, 0x2C, 0x04, 0x62, 0x6C, 0xCC,
		0x2D, 0x40, 0xE1, 0x6B, 0x30, 0x81, 0x10, 0xC8, 0xEF, 0x33, 0x7C, 0x61,
		0x17, 0x05, 0x93, 0x2F, 0x9C, 0x9C, 0x38, 0x1D, 0xE9, 0x44, 0x14, 0xA5,
		0x80, 0x00, 0x09, 0x20, 0x21, 0x43, 0x42, 0xFF, 0xFB, 0x10, 0x64, 0x03,
		0x81, 0x30, 0xAE, 0x07, 0x59, 0x21, 0x38, 0x40, 0x9A, 0x0E, 0xE0, 0xEA,
		0xE4, 0x05, 0xE5, 0x03, 0x42, 0x00, 0x17, 0x75, 0x80, 0x08, 0xC0, 0x30,
		0x3C, 0x85, 0x6A, 0x11, 0x11, 0x1C, 0x9C, 0x21, 0x08, 0x97, 0x53, 0xFD,
		0x4C, 0xA5, 0x06, 0xF2, 0x4D, 0xC8, 0xEC, 0x83, 0x4D, 0xA0, 0xC0, 0x81,
		0x50, 0x01, 0x29, 0x10, 0xF0, 0xDB, 0x57, 0x84, 0x96, 0x89, 0x1B, 0x25,
		0x90, 0x61, 0xB7, 0x23, 0x00, 0x30, 0x83, 0x03, 0x5B, 0xA9, 0x91, 0x4A,
		0x2E, 0x72, 0xAF, 0xFF, 0x68, 0x40, 0x81, 0x54, 0x03, 0x3B, 0x01, 0x1A,
		0x1D, 0x80, 0xC1, 0xEA, 0x20, 0x8F, 0xE0, 0x39, 0x02, 0x00, 0x07, 0x29,
		0x81, 0x86, 0x4F, 0xFF, 0xFB, 0x12, 0x64, 0x03, 0x8B, 0xF0, 0x8F, 0x06,
		0x55, 0xA8, 0x18, 0x38, 0x18, 0x0D, 0xA1, 0x59, 0xE0, 0x03, 0x27, 0x05,
		0x02, 0x78, 0x3F, 0x50, 0x0C, 0x18, 0x45, 0x20, 0x37, 0x83, 0xE8, 0xC0,
		0x1C, 0x24, 0x0C, 0x21, 0x94, 0x88, 0xA0, 0xC8, 0xB1, 0x5B, 0xCF, 0xD1,
		0x8B, 0x55, 0x06, 0xB9, 0x27, 0xFF, 0xE5, 0x6E, 0x39, 0x2E, 0x4C, 0x00,
		0xF1, 0xAF, 0xF0, 0xEE, 0xE3, 0x6A, 0x4C, 0x6F, 0x7B, 0x53, 0x0D, 0x62,
		0xCA, 0x05, 0xF3, 0xE0, 0x3F, 0xE3, 0x41, 0x63, 0x43, 0x52, 0x71, 0x9A,
		0xAB, 0x99, 0xE0, 0x04, 0x40, 0x5C, 0xD0, 0xB2, 0x21, 0x6F, 0x19, 0xBB,
		0x11, 0x2A, 0xB0, 0x00, 0x66, 0xAF, 0x9C, 0x63, 0xE1, 0x00, 0x72, 0x0C,
		0xFF, 0xFB, 0x10, 0x64, 0x05, 0x0F, 0x70, 0xA1, 0x08, 0xD7, 0x80, 0x2F,
		0x30, 0xA2, 0x0D, 0x40, 0xBA, 0x65, 0x03, 0x06, 0x03, 0x42, 0x40, 0x1F,
		0x6A, 0x00, 0xE0, 0xC2, 0x80, 0x36, 0x84, 0x2A, 0x80, 0x37, 0x94, 0x4D,
		0x3C, 0x9A, 0xCA, 0x42, 0x30, 0x23, 0x9F, 0x93, 0x93, 0x6D, 0x20, 0x00,
		0x02, 0xFD, 0xE1, 0x67, 0x26, 0xC1, 0xE1, 0x70, 0xB6, 0x22, 0xF1, 0x19,
		0x67, 0xA2, 0x20, 0xC2, 0x39, 0x6E, 0xED, 0x18, 0x19, 0x18, 0x3A, 0x84,
		0xA1, 0xBA, 0x9F, 0x5B, 0x84, 0x50, 0x1A, 0x31, 0x0D, 0x99, 0x12, 0xA6,
		0x07, 0x8F, 0x1A, 0xD1, 0x96, 0x45, 0x0F, 0x82, 0x51, 0x18, 0x70, 0x2B,
		0xE6, 0x08, 0x3C, 0x98, 0x23, 0x51, 0xEE, 0x45, 0xFF, 0xFB, 0x12, 0x44,
		0x06, 0x81, 0xF0, 0x74, 0x07, 0x57, 0x80, 0x38, 0x30, 0x98, 0x0F, 0x40,
		0xCA, 0xF0, 0x07, 0x26, 0x13, 0x01, 0xCC, 0x13, 0x85, 0xA0, 0x04, 0xC0,
		0x30, 0x39, 0x03, 0xAB, 0x40, 0x1C, 0x24, 0x48, 0xB9, 0x58, 0x02, 0x6B,
		0x45, 0xF8, 0x06, 0xC0, 0x93, 0x07, 0xA6, 0x00, 0xC5, 0x84, 0x13, 0x6E,
		0x54, 0x66, 0x6B, 0x82, 0x8B, 0x40, 0x02, 0x11, 0x53, 0x6A, 0xA5, 0x4E,
		0xE5, 0x3B, 0xF4, 0xF1, 0x24, 0xB3, 0x6A, 0x82, 0xE4, 0xF1, 0x1E, 0x4C,
		0x1C, 0xAE, 0x87, 0x9C, 0xFD, 0xF5, 0xD6, 0xD8, 0xDB, 0x65, 0x19, 0xA6,
		0x34, 0x64, 0xA2, 0x05, 0x91, 0x00, 0xAE, 0x7F, 0x57, 0x7F, 0x0E, 0x02,
		0x07, 0x85, 0x8F, 0x8C, 0x4A, 0xFF, 0xFB, 0x10, 0x64, 0x0B, 0x8B, 0x70,
		0x7D, 0x07, 0x56, 0x00, 0x1A, 0x40, 0x20, 0x0F, 0x00, 0xE9, 0xE0, 0x2B,
		0x6A, 0x15, 0x01, 0xA0, 0x1D, 0x5C, 0xA0, 0x65, 0x22, 0x60, 0x35, 0x83,
		0xE9, 0x94, 0x5C, 0x24, 0x4C, 0x21, 0x24, 0x99, 0xDB, 0xE7, 0x0E, 0xC1,
		0x12, 0x59, 0x43, 0x7E, 0x14, 0x85, 0x08, 0xC4, 0x8E, 0x13, 0xFE, 0x8E,
		0xFF, 0x42, 0x1C, 0x31, 0x09, 0xF0, 0xF0, 0x8F, 0x45, 0xF8, 0x17, 0x8A,
		0x04, 0xAD, 0x7B, 0x05, 0xC0, 0x04, 0xA3, 0xB8, 0x50, 0x0D, 0x83, 0x62,
		0xB0, 0xA1, 0x74, 0x93, 0xA6, 0x09, 0x2A, 0xAA, 0xA8, 0xAC, 0xB2, 0x0B,
		0xB8, 0xCC, 0x34, 0x1A, 0x99, 0x01, 0x90, 0xB8, 0x38, 0x03, 0x9C, 0xD2,
		0x35, 0xFF, 0xFB, 0x12, 0x64, 0x11, 0x01, 0xF0, 0x8E, 0x07, 0x5B, 0xA8,
		0x03, 0x48, 0x1A, 0x0F, 0x20, 0xBA, 0xB0, 0x00, 0x2F, 0x01, 0x02, 0x10,
		0x13, 0x95, 0xA0, 0x04, 0x40, 0x30, 0x3C, 0x83, 0xA9, 0xC0, 0x03, 0x60,
		0x45, 0x47, 0x6C, 0x36, 0xB4, 0x01, 0x63, 0x41, 0x40, 0x4A, 0x87, 0x42,
		0xB7, 0xF2, 0x5D, 0x3D, 0x60, 0x31, 0xA5, 0x83, 0xA2, 0xA2, 0x2B, 0xA2,
		0xB5, 0x7A, 0x4A, 0xB6, 0x01, 0x06, 0x2B, 0xC5, 0x8D, 0xC6, 0x0B, 0x00,
		0x93, 0x10, 0x2F, 0x19, 0x4F, 0x80, 0x5F, 0x86, 0xFB, 0x7A, 0x0C, 0x02,
		0xA0, 0x00, 0x39, 0xA4, 0x4C, 0x55, 0xE1, 0xDF, 0xCB, 0x40, 0xB0, 0x38,
		0x6F, 0x38, 0xCD, 0x14, 0x1E, 0x93, 0x26, 0x3E, 0xEF, 0xB0, 0xFF, 0xFB,
		0x10, 0x64, 0x13, 0x0F, 0x30, 0x72, 0x09, 0xD8, 0x00, 0x1A, 0x28, 0xA0,
		0x0E, 0x60, 0xFA, 0xB8, 0x05, 0xE3, 0x23, 0x41, 0xD0, 0x27, 0x5E, 0x00,
		0xE4, 0x42, 0x80, 0x38, 0x83, 0xE9, 0x80, 0x1C, 0x88, 0x54, 0xC0, 0x5E,
		0x0C, 0x6F, 0xF4, 0xF2, 0x7E, 0xA0, 0x44, 0x26, 0x20, 0x18, 0xE6, 0x81,
		0xA5, 0x9D, 0xF1, 0xFD, 0x04, 0x95, 0x6E, 0x4D, 0xA9, 0x60, 0xBF, 0x3B,
		0x8A, 0x45, 0x50, 0xAC, 0x9C, 0x30, 0xC9, 0xC8, 0xF1, 0xA8, 0xA8, 0x8B,
		0x0A, 0x16, 0xB0, 0xAF, 0x54, 0xC6, 0xF8, 0xD1, 0xFF, 0x83, 0x16, 0x80,
		0xAB, 0x14, 0x40, 0x00, 0x99, 0xCB, 0x25, 0x38, 0xC0, 0x94, 0x7B, 0x24,
		0xAF, 0x67, 0x58, 0xD4, 0x88, 0xD0, 0xFF, 0xFB, 0x12, 0x64, 0x18, 0x01,
		0x30, 0x71, 0x09, 0xD6, 0x80, 0x19, 0x28, 0xA8, 0x0D, 0xE1, 0xAA, 0x50,
		0x0B, 0x22, 0x15, 0x02, 0x14, 0x17, 0x75, 0xA0, 0x05, 0x80, 0x20, 0x3B,
		0x02, 0xAC, 0x90, 0x05, 0x30, 0x0C, 0x15, 0x14, 0x27, 0x57, 0x16, 0x40,
		0x05, 0x00, 0x62, 0xE4, 0xFD, 0xEA, 0x08, 0x10, 0x3E, 0x80, 0x00, 0x06,
		0x26, 0x78, 0x26, 0x22, 0x2D, 0x15, 0xDE, 0xFE, 0x1C, 0xEA, 0xF7, 0x36,
		0x55, 0xDE, 0x23, 0x31, 0x33, 0x00, 0x80, 0x24, 0xC2, 0x6C, 0x80, 0x59,
		0x7C, 0x67, 0x0D, 0x50, 0x4B, 0x06, 0x28, 0xC8, 0x33, 0xA5, 0x13, 0x93,
		0x96, 0x62, 0xCF, 0x74, 0x75, 0x9A, 0x17, 0x01, 0x34, 0x22, 0x2F, 0x80,
		0xBE, 0x69, 0x3D, 0xFF, 0xFB, 0x10, 0x64, 0x1C, 0x81, 0x30, 0x89, 0x05,
		0xDA, 0xC8, 0x09, 0xC0, 0x98, 0x0E, 0xE1, 0x1A, 0x10, 0x03, 0x6D, 0x15,
		0x01, 0xE4, 0x17, 0x5C, 0x00, 0x33, 0x22, 0x00, 0x35, 0x83, 0xEB, 0x60,
		0x03, 0xBC, 0x14, 0xB4, 0xD3, 0x4C, 0xBA, 0xE5, 0x10, 0x8B, 0x16, 0x1C,
		0xD9, 0x80, 0xB1, 0x5D, 0xC3, 0x06, 0x56, 0xD4, 0x42, 0x35, 0x8E, 0x40,
		0x3A, 0xF8, 0x38, 0x46, 0x30, 0x4E, 0x88, 0x07, 0xAE, 0x6A, 0x3E, 0xA2,
		0x13, 0xAE, 0x1B, 0xB4, 0xDB, 0x2A, 0xD0, 0x16, 0x57, 0x68, 0x49, 0x4A,
		0xBC, 0x33, 0xAD, 0xCB, 0x9F, 0x6D, 0xD2, 0x44, 0xFD, 0x55, 0x4A, 0x10,
		0x42, 0xAF, 0x0C, 0xEB, 0x21, 0x0E, 0x84, 0x7C, 0x62, 0x19, 0xFE, 0xFF,
		0xFB, 0x12, 0x44, 0x20, 0x0F, 0x30, 0x79, 0x09, 0x56, 0x00, 0x38, 0x10,
		0xA8, 0x0F, 0xA1, 0x2B, 0x74, 0x09, 0x82, 0x15, 0x01, 0xA0, 0x25, 0x56,
		0x00, 0x60, 0xA2, 0xA0, 0x35, 0x04, 0xAA, 0xC0, 0x0C, 0x14, 0x54, 0x36,
		0x7B, 0x44, 0x4E, 0x0B, 0x1F, 0xE4, 0x7A, 0x40, 0x10, 0x01, 0xE4, 0x1D,
		0x00, 0xE0, 0x61, 0x1E, 0x38, 0x18, 0x54, 0x87, 0xDB, 0xD0, 0x29, 0x3E,
		0x24, 0x03, 0x66, 0xE4, 0x37, 0x8C, 0x15, 0xFE, 0x1B, 0xEC, 0xE8, 0x30,
		0x44, 0x05, 0x04, 0xA3, 0x86, 0x17, 0x69, 0x26, 0x1B, 0x07, 0xAF, 0xC0,
		0xFD, 0xF5, 0x43, 0x60, 0x07, 0x70, 0xED, 0xE7, 0x55, 0x36, 0x4C, 0xD6,
		0x7D, 0x43, 0x97, 0x47, 0x45, 0xD9, 0xC8, 0x74, 0xFF, 0xFB, 0x10, 0x64,
		0x26, 0x0B, 0xF0, 0x7A, 0x05, 0xD5, 0x80, 0x12, 0xC8, 0x90, 0x0E, 0xA0,
		0xBA, 0x95, 0x00, 0xD1, 0x05, 0x01, 0xA4, 0x27, 0x5E, 0xA0, 0x60, 0xA2,
		0xA0, 0x39, 0x82, 0xA9, 0x40, 0x06, 0x60, 0x48, 0x8F, 0x50, 0xDD, 0x80,
		0x20, 0x0B, 0x9D, 0x4C, 0xA0, 0x5D, 0x1A, 0xD9, 0x5D, 0x04, 0x37, 0x70,
		0x4A, 0xDC, 0xFE, 0x16, 0x1A, 0x2B, 0x04, 0xF7, 0x04, 0xAC, 0x10, 0x25,
		0xC4, 0x17, 0x0E, 0x7F, 0x1F, 0x96, 0xFE, 0x58, 0x50, 0x00, 0x60, 0x01,
		0x23, 0xF7, 0x92, 0xF4, 0x34, 0x0A, 0xBF, 0x81, 0x4D, 0x87, 0x04, 0x1A,
		0x11, 0x76, 0xCF, 0x5A, 0x00, 0x00, 0x01, 0xCE, 0x88, 0x68, 0x6B, 0x10,
		0xE0, 0x73, 0x0B, 0xC2, 0xFF, 0xFB, 0x12, 0x64, 0x2B, 0x03, 0x30, 0x91,
		0x06, 0xD6, 0xA8, 0x38, 0x30, 0xA8, 0x0F, 0x00, 0xFB, 0x14, 0x00, 0x4C,
		0x01, 0x02, 0x94, 0x47, 0x4E, 0x01, 0x65, 0x42, 0x80, 0x3C, 0x84, 0x6A,
		0x50, 0x07, 0x8C, 0x1C, 0x80, 0x1C, 0x2B, 0xD6, 0x19, 0xF8, 0x5F, 0xF8,
		0x6B, 0x5A, 0xBE, 0xDD, 0x29, 0x49, 0x6C, 0xA5, 0x7E, 0x8C, 0xD2, 0x0F,
		0xC6, 0x3F, 0x57, 0x92, 0x0B, 0x8A, 0x3C, 0xC5, 0x20, 0x63, 0x40, 0x05,
		0x8C, 0xDF, 0x40, 0x2B, 0x0B, 0x84, 0x77, 0xE0, 0xCF, 0x21, 0xCD, 0xE0,
		0x73, 0x20, 0xC9, 0xC1, 0x34, 0x48, 0xFA, 0xDC, 0xCE, 0xBA, 0x67, 0x60,
		0x07, 0x36, 0xEF, 0x13, 0x1D, 0x0B, 0x25, 0x10, 0xE7, 0x54, 0x28, 0x92,
		0xC6, 0xFF, 0xFB, 0x10, 0x64, 0x2B, 0x03, 0xB0, 0xCD, 0x16, 0x5E, 0x68,
		0x09, 0x28, 0x3C, 0x0F, 0x61, 0x2A, 0x30, 0x03, 0x23, 0x14, 0x02, 0x1C,
		0x25, 0x3A, 0x00, 0x72, 0x22, 0xA0, 0x32, 0x83, 0xE8, 0x14, 0x09, 0x24,
		0x5C, 0x81, 0xBC, 0x8F, 0x5F, 0x40, 0x34, 0x8B, 0xC6, 0x4C, 0x04, 0xFA,
		0x9E, 0x02, 0x58, 0x9A, 0x83, 0x39, 0xDB, 0xD4, 0x04, 0xF9, 0xC4, 0x2D,
		0x8E, 0x15, 0xB3, 0x81, 0x15, 0x25, 0x3A, 0xB8, 0x3D, 0x46, 0x46, 0x2F,
		0x82, 0x9D, 0xCB, 0x78, 0x42, 0xD1, 0x9D, 0x52, 0x19, 0x2B, 0x49, 0xB2,
		0xF5, 0xEB, 0xD7, 0xEF, 0xFF, 0x2D, 0x2A, 0x02, 0x60, 0x04, 0x6F, 0x26,
		0xF1, 0x5A, 0x87, 0xBE, 0xE5, 0x07, 0x5D, 0x8B, 0xC1, 0xFF, 0xFB, 0x12,
		0x64, 0x29, 0x83, 0xF0, 0x95, 0x09, 0xD5, 0xA8, 0x38, 0x28, 0xA8, 0x0F,
		0x41, 0x1A, 0x20, 0x2B, 0x03, 0x22, 0x02, 0x68, 0x37, 0x56, 0xA0, 0xE0,
		0x42, 0xA0, 0x3C, 0x84, 0xA7, 0x81, 0x0D, 0x3C, 0x8C, 0x7C, 0x83, 0xF4,
		0x76, 0xE4, 0x5E, 0xA5, 0x8B, 0x9D, 0x75, 0xA9, 0xD0, 0x94, 0x59, 0x08,
		0x32, 0xFB, 0xFF, 0xA1, 0x9D, 0xF6, 0xF6, 0xD4, 0x24, 0x13, 0xE6, 0x66,
		0x4B, 0x8B, 0x6F, 0x32, 0x04, 0x7F, 0x92, 0xE4, 0xDB, 0xCE, 0xD9, 0xA7,
		0x38, 0x80, 0xF0, 0xEA, 0x59, 0x7F, 0x81, 0x07, 0x4F, 0x7D, 0x46, 0xC0,
		0x07, 0x40, 0xF2, 0x0B, 0x04, 0xFE, 0x08, 0xD5, 0x27, 0x36, 0xBC, 0x7A,
		0xB6, 0xF4, 0x7F, 0x21, 0x49, 0x74, 0xFF, 0xFB, 0x10, 0x64, 0x29, 0x83,
		0xF0, 0x89, 0x09, 0xD4, 0xA8, 0x18, 0x28, 0xA8, 0x0F, 0xA1, 0x2A, 0x00,
		0x07, 0x23, 0x14, 0x01, 0xE8, 0x23, 0x54, 0xA0, 0xE0, 0x62, 0xA0, 0x3A,
		0x84, 0xA8, 0x40, 0x1C, 0x98, 0x54, 0x2B, 0xBB, 0x3A, 0x54, 0x73, 0x17,
		0x0D, 0x53, 0xFF, 0xF2, 0x0E, 0xEC, 0xEB, 0x94, 0x85, 0xA0, 0x9A, 0xE0,
		0x80, 0xC0, 0x56, 0xB3, 0xCB, 0xC9, 0xBF, 0x4E, 0x00, 0x56, 0x40, 0xA3,
		0x70, 0xDC, 0x9B, 0xC6, 0x8F, 0x2C, 0xE7, 0x67, 0xF5, 0x2A, 0x74, 0xA9,
		0x46, 0x4E, 0xA7, 0x8D, 0xC0, 0xF0, 0xF7, 0xE1, 0x80, 0x30, 0x00, 0x04,
		0x45, 0xF0, 0x09, 0xA4, 0xE1, 0x74, 0xF7, 0x38, 0x5D, 0xA7, 0xF4, 0xB3,
		0xAE, 0x6B, 0xFF, 0xFB, 0x12, 0x64, 0x2C, 0x03, 0xB0, 0x81, 0x09, 0xD6,
		0x28, 0xF8, 0x11, 0x18, 0x0E, 0x41, 0x2A, 0x20, 0x23, 0x05, 0x30, 0x01,
		0xE8, 0x17, 0x4E, 0x00, 0x65, 0x22, 0x80, 0x36, 0x02, 0xE9, 0x14, 0x03,
		0x60, 0x4C, 0x96, 0xF0, 0xD7, 0x76, 0x01, 0x51, 0xA5, 0x2D, 0xA7, 0x9D,
		0x04, 0xFA, 0x50, 0x17, 0xAF, 0xB0, 0xAF, 0x0E, 0x20, 0x89, 0x08, 0xDE,
		0x04, 0x38, 0xED, 0x48, 0xBB, 0x90, 0x21, 0x4D, 0x02, 0xA1, 0x7C, 0xFF,
		0xED, 0x80, 0x00, 0x00, 0x05, 0x1F, 0x1C, 0x2D, 0x63, 0x19, 0xBC, 0x0D,
		0x87, 0x0F, 0x65, 0x3B, 0x9D, 0xD8, 0x08, 0x40, 0x00, 0xBD, 0xDC, 0x03,
		0x80, 0xB3, 0xF7, 0xF4, 0xF4, 0xF5, 0x4D, 0xE4, 0x87, 0x8E, 0xB0, 0xFF,
		0xFB, 0x10, 0x64, 0x30, 0x83, 0xB0, 0x53, 0x09, 0x54, 0x00, 0x18, 0x28,
		0xA8, 0x0E, 0xC1, 0x3A, 0x25, 0x01, 0x33, 0x11, 0x02, 0x34, 0x37, 0x54,
		0xA0, 0xBC, 0x42, 0xE0, 0x3B, 0x84, 0xA8, 0x01, 0x09, 0x88, 0xC4, 0xA3,
		0xBF, 0xA6, 0xA2, 0x80, 0xC4, 0x2D, 0xA8, 0x00, 0x52, 0x22, 0x1D, 0x46,
		0x78, 0xAC, 0x52, 0x8E, 0x02, 0x01, 0x8A, 0x27, 0x40, 0x04, 0xB2, 0xE1,
		0x08, 0x1F, 0x23, 0x09, 0xDF, 0xE1, 0x9A, 0xDF, 0xA2, 0x3A, 0xC4, 0xC4,
		0x6D, 0x85, 0x13, 0x05, 0xDC, 0x55, 0xB1, 0x2C, 0x4E, 0x82, 0x2F, 0x12,
		0xF5, 0x45, 0xEF, 0x40, 0xCA, 0xB4, 0x1D, 0xD4, 0x02, 0x8C, 0xF6, 0x40,
		0x51, 0x11, 0x02, 0x49, 0x04, 0x8C, 0x41, 0xFF, 0xFB, 0x12, 0x64, 0x35,
		0x83, 0x30, 0xAF, 0x06, 0xDE, 0xE8, 0x08, 0x10, 0x8C, 0x0C, 0x40, 0x9A,
		0x85, 0x00, 0xAF, 0x11, 0x81, 0x24, 0x25, 0x52, 0x00, 0x60, 0x42, 0xA0,
		0x3D, 0x84, 0xAA, 0xD0, 0x06, 0x0C, 0x55, 0x03, 0xC0, 0x33, 0x7C, 0x3B,
		0x27, 0x62, 0xF6, 0xAA, 0x81, 0x61, 0xD2, 0x17, 0xC8, 0x80, 0x35, 0xFC,
		0x51, 0x91, 0x49, 0x4B, 0x02, 0x07, 0xE4, 0x7A, 0x7C, 0x1E, 0xC1, 0xD8,
		0x08, 0x91, 0xA1, 0x16, 0x7C, 0x5A, 0x7A, 0xBE, 0xD5, 0x6E, 0x5E, 0xBC,
		0xAB, 0x11, 0x11, 0x2B, 0xBC, 0xB1, 0x2B, 0x64, 0x2B, 0xAA, 0xD1, 0x03,
		0x65, 0x76, 0x72, 0x9D, 0x40, 0x70, 0x2F, 0x50, 0x01, 0x49, 0x97, 0x60,
		0x08, 0x1E, 0x69, 0xC4, 0xFF, 0xFB, 0x10, 0x64, 0x3A, 0x83, 0x30, 0x7A,
		0x09, 0x54, 0x28, 0x18, 0x18, 0xA8, 0x0E, 0xE0, 0xAA, 0xE4, 0x00, 0x29,
		0x01, 0x01, 0x6C, 0x25, 0x4C, 0x00, 0x60, 0xA2, 0xA0, 0x3B, 0x02, 0x6A,
		0x90, 0x00, 0xA4, 0x05, 0x45, 0x61, 0x34, 0x8A, 0xE3, 0x8C, 0xE6, 0xE4,
		0xA6, 0xC9, 0x9B, 0x10, 0x6B, 0xAF, 0x7E, 0x8A, 0x9E, 0xA8, 0xCF, 0xF6,
		0x71, 0x98, 0x75, 0xB4, 0x08, 0xF8, 0xFA, 0x9F, 0xE0, 0xB0, 0x98, 0xC0,
		0xC6, 0x1A, 0xFD, 0x50, 0x1E, 0x38, 0x71, 0x89, 0x04, 0x3F, 0xF5, 0xEC,
		0x02, 0xFC, 0xCE, 0x88, 0xE5, 0xCC, 0x77, 0x54, 0xC1, 0x57, 0xA6, 0xDB,
		0x3B, 0x04, 0x4D, 0x44, 0x28, 0xED, 0xE0, 0x11, 0x81, 0xBA, 0xE6, 0xF1,
		0xFF, 0xFB, 0x12, 0x64, 0x40, 0x0F, 0x30, 0x82, 0x09, 0xD1, 0x00, 0x19,
		0x10, 0xA0, 0x0F, 0x61, 0x29, 0x60, 0x4A, 0xAF, 0x23, 0x02, 0x18, 0x27,
		0x4A, 0x00, 0x64, 0xA2, 0x80, 0x3C, 0x83, 0xEA, 0x90, 0x07, 0xA4, 0x44,
		0xC5, 0x86, 0x5E, 0x83, 0x8E, 0x65, 0x54, 0xF5, 0x5C, 0x4F, 0x68, 0x15,
		0x7B, 0xEB, 0x17, 0xED, 0xE4, 0x79, 0x2D, 0x08, 0x53, 0xC8, 0x8B, 0x40,
		0x0A, 0x1E, 0x26, 0xED, 0xAD, 0xF5, 0xFF, 0xCE, 0xC4, 0x2F, 0xB9, 0x4C,
		0x50, 0x03, 0x28, 0x3C, 0xD5, 0xE8, 0x38, 0x1C, 0x01, 0xB0, 0x03, 0x00,
		0x00, 0x76, 0x91, 0x87, 0xF7, 0x89, 0xBF, 0xDF, 0x67, 0x94, 0x48, 0xC9,
		0xA8, 0x47, 0xCF, 0x7E, 0x7F, 0x92, 0x80, 0xDE, 0x02, 0xFF, 0xFB, 0x10,
		0x64, 0x42, 0x8F, 0xF0, 0x81, 0x09, 0x52, 0x80, 0x38, 0x18, 0xA0, 0x0E,
		0x61, 0x29, 0xE0, 0x0B, 0x03, 0x15, 0x02, 0x14, 0x25, 0x44, 0x05, 0x60,
		0x64, 0x40, 0x3B, 0x83, 0x67, 0xC0, 0x04, 0xE0, 0x0D, 0x08, 0x06, 0x81,
		0x10, 0x18, 0xE2, 0x1D, 0x19, 0x83, 0xCC, 0x3B, 0x70, 0x45, 0xC8, 0x17,
		0x46, 0x04, 0x47, 0xDB, 0x05, 0x81, 0xD5, 0x9C, 0x31, 0xB3, 0x96, 0xF7,
		0x81, 0x00, 0x71, 0x80, 0x03, 0xF2, 0xCC, 0x31, 0x03, 0x64, 0x1B, 0x89,
		0x52, 0x01, 0x6A, 0x69, 0x98, 0xD1, 0x23, 0xC0, 0x0B, 0x34, 0x81, 0xFE,
		0x30, 0xD8, 0xC4, 0x92, 0x5F, 0x08, 0xDE, 0x78, 0xBC, 0x78, 0xBB, 0x9D,
		0x39, 0xFC, 0xE2, 0x77, 0x41, 0xFF, 0xFB, 0x12, 0x64, 0x45, 0x8F, 0x10,
		0x9A, 0x09, 0x50, 0x80, 0x39, 0x40, 0xA0, 0x0E, 0xE1, 0x29, 0xB0, 0x07,
		0x4B, 0x14, 0x01, 0x50, 0x25, 0x48, 0x00, 0x60, 0x42, 0xA0, 0x35, 0x01,
		0xAB, 0xB4, 0x00, 0x30, 0x04, 0xF0, 0x7D, 0x80, 0x8A, 0xEB, 0x50, 0x40,
		0x28, 0xCB, 0x91, 0x07, 0x9D, 0xCB, 0x9E, 0xBB, 0xBE, 0x85, 0xC8, 0x8D,
		0xE2, 0xB5, 0x80, 0xA9, 0x14, 0x39, 0xFC, 0x02, 0xD1, 0xF3, 0x4D, 0x78,
		0xFD, 0x60, 0x40, 0x00, 0x76, 0x71, 0x92, 0x78, 0x46, 0xD1, 0x58, 0x4A,
		0x89, 0x24, 0x6F, 0xFD, 0xC8, 0x43, 0xE4, 0xC3, 0x11, 0xD2, 0xC9, 0x06,
		0x69, 0x0A, 0x90, 0x6E, 0x61, 0x50, 0xEA, 0xF8, 0xFF, 0x49, 0x2B, 0x2C,
		0x00, 0x58, 0xFF, 0xFB, 0x10, 0x64, 0x4B, 0x0F, 0x30, 0x46, 0x09, 0x52,
		0x00, 0x0F, 0x88, 0x98, 0x0F, 0x01, 0x29, 0x60, 0x42, 0x87, 0x31, 0x02,
		0x0C, 0x17, 0x44, 0x00, 0x23, 0x00, 0x40, 0x39, 0x03, 0xA9, 0x50, 0x06,
		0x0C, 0x55, 0x28, 0x0C, 0x51, 0xCC, 0xC7, 0x5A, 0xA7, 0x8D, 0x9A, 0x5D,
		0xA0, 0x27, 0xD8, 0xF6, 0xE8, 0x75, 0x79, 0xC1, 0x48, 0xBE, 0x60, 0x44,
		0x81, 0x50, 0x06, 0x4D, 0x5A, 0x43, 0x21, 0x90, 0xBF, 0x15, 0x70, 0xDE,
		0x64, 0x0B, 0x7C, 0xC5, 0xA6, 0xCE, 0x9D, 0x77, 0x2D, 0x04, 0xF5, 0x7B,
		0x51, 0xB1, 0xB3, 0x96, 0x01, 0x29, 0xF3, 0x07, 0x1F, 0xC0, 0x20, 0x45,
		0xAD, 0x7C, 0x0C, 0x3A, 0x02, 0x91, 0xAF, 0x03, 0x12, 0x3D, 0xFF, 0xFB,
		0x12, 0x64, 0x51, 0x8F, 0xF0, 0x4D, 0x09, 0x51, 0x80, 0x0F, 0x10, 0xA8,
		0x0E, 0x01, 0xA9, 0xB0, 0x01, 0x93, 0x13, 0x01, 0x00, 0x17, 0x46, 0x00,
		0x3C, 0x02, 0xA0, 0x3C, 0x04, 0xA5, 0x00, 0x0D, 0x34, 0x64, 0x93, 0x60,
		0x8E, 0x05, 0x59, 0x75, 0x04, 0x07, 0xE6, 0x50, 0x97, 0xE8, 0x84, 0xCE,
		0x0C, 0xE5, 0xAF, 0x8D, 0xD1, 0x06, 0x05, 0x61, 0x60, 0x04, 0x5F, 0x25,
		0x12, 0x69, 0xC2, 0x19, 0x35, 0x75, 0x72, 0x13, 0x8A, 0xF3, 0x1D, 0xA6,
		0x20, 0x50, 0x16, 0x1A, 0x56, 0xE0, 0x39, 0xF3, 0xE2, 0x80, 0x14, 0x07,
		0xC4, 0xD2, 0x81, 0x70, 0x21, 0x54, 0x64, 0x2B, 0x1F, 0xD9, 0x06, 0x5E,
		0x11, 0x39, 0xDB, 0xD2, 0x06, 0x00, 0x09, 0xFF, 0xFB, 0x10, 0x64, 0x5C,
		0x8B, 0xB0, 0x5B, 0x09, 0x51, 0x00, 0x18, 0x10, 0xA8, 0x0F, 0x01, 0x29,
		0xB5, 0x03, 0x09, 0x15, 0x01, 0x14, 0x15, 0x4A, 0xA0, 0x33, 0x02, 0x60,
		0x3C, 0x03, 0xE4, 0x80, 0x0D, 0x1C, 0x54, 0x1E, 0x2F, 0xBC, 0x6C, 0x23,
		0x28, 0xAA, 0xA2, 0x3C, 0x0F, 0xF2, 0x44, 0xC9, 0xC3, 0xAD, 0x44, 0xEB,
		0x2A, 0x03, 0x42, 0x19, 0xC8, 0x0B, 0x2A, 0x7E, 0xE0, 0xD6, 0xF6, 0xE3,
		0x39, 0x67, 0x46, 0x5E, 0x45, 0x65, 0xB9, 0x7F, 0x1A, 0xA2, 0x8D, 0x60,
		0xDA, 0x4C, 0x56, 0x0A, 0x58, 0x6A, 0x81, 0x23, 0x9A, 0x18, 0xC3, 0x86,
		0xE2, 0x0C, 0x40, 0x21, 0x31, 0xF4, 0x36, 0xD9, 0x61, 0x82, 0xE1, 0xC3,
		0xB9, 0x7E, 0x41, 0xFF, 0xFB, 0x12, 0x64, 0x65, 0x8F, 0xF0, 0x7C, 0x09,
		0x4F, 0x00, 0x18, 0x30, 0xA0, 0x0E, 0xE1, 0x29, 0x10, 0x03, 0x15, 0x13,
		0x01, 0xBC, 0x25, 0x3E, 0x00, 0x60, 0x62, 0x80, 0x3D, 0x84, 0xA5, 0x40,
		0x0D, 0x18, 0x54, 0x19, 0xBF, 0x83, 0x26, 0x41, 0x55, 0x47, 0x02, 0xAF,
		0xCC, 0x95, 0x6A, 0xC1, 0x56, 0x7D, 0x07, 0xFE, 0x09, 0x00, 0xB4, 0x25,
		0x82, 0x85, 0x90, 0x38, 0x91, 0x3D, 0xCA, 0x83, 0xB1, 0x21, 0x83, 0x55,
		0x66, 0x34, 0x6A, 0x20, 0x24, 0xA8, 0xB1, 0xB3, 0xC0, 0xFA, 0xD9, 0x31,
		0x47, 0x28, 0x66, 0x46, 0x1D, 0x11, 0x86, 0x0E, 0x6A, 0x54, 0x95, 0xE8,
		0x38, 0x59, 0xD8, 0xCE, 0xE7, 0x65, 0x50, 0x72, 0x80, 0x0D, 0x10, 0x26,
		0xFF, 0xFB, 0x10, 0x64, 0x6A, 0x03, 0xF0, 0x7A, 0x09, 0x55, 0x20, 0x09,
		0x18, 0xA8, 0x0E, 0x61, 0x29, 0x30, 0x03, 0x45, 0x17, 0x01, 0xB8, 0x25,
		0x3E, 0x00, 0x60, 0x42, 0x80, 0x39, 0x84, 0xA3, 0xC0, 0x0C, 0x50, 0x4C,
		0x6D, 0xF0, 0x96, 0x06, 0x2B, 0x6C, 0x6B, 0xE0, 0xC0, 0x60, 0xAA, 0x01,
		0xCB, 0x0D, 0x25, 0x82, 0x33, 0x92, 0xE9, 0xF0, 0xBC, 0xBF, 0x06, 0x6A,
		0x44, 0x37, 0x48, 0xC3, 0xE4, 0x2B, 0x0C, 0x57, 0x70, 0xC5, 0x0B, 0x04,
		0x58, 0x37, 0xF0, 0xE1, 0x63, 0x08, 0x13, 0x3F, 0x7C, 0xFF, 0xE3, 0x64,
		0xE8, 0xF2, 0xC9, 0xA0, 0x49, 0x15, 0x3C, 0x0C, 0xCC, 0x0E, 0x80, 0xF6,
		0xEC, 0x2B, 0x7E, 0x01, 0x4F, 0x83, 0x01, 0xD3, 0xFF, 0xFB, 0x12, 0x64,
		0x6F, 0x03, 0xB0, 0x6F, 0x05, 0xCE, 0x80, 0x18, 0xC8, 0x90, 0x0F, 0x61,
		0x29, 0x95, 0x03, 0x06, 0x15, 0x01, 0xC8, 0x25, 0x3A, 0xA0, 0x60, 0xC2,
		0xA0, 0x3C, 0x04, 0xA5, 0x00, 0x0C, 0x9C, 0x64, 0x15, 0x29, 0x2C, 0x91,
		0x87, 0x2D, 0x15, 0x97, 0x9E, 0x3E, 0x3F, 0xFF, 0x06, 0x62, 0x31, 0x18,
		0x0C, 0x40, 0x03, 0x2C, 0x51, 0xCD, 0x28, 0x3D, 0x35, 0x57, 0x77, 0xFF,
		0x83, 0x3E, 0x72, 0xF0, 0x27, 0xC5, 0x83, 0xE1, 0x8D, 0xC0, 0xC5, 0x25,
		0xD0, 0x11, 0xA4, 0xB0, 0x07, 0x00, 0x3B, 0x4A, 0xC6, 0xA6, 0x90, 0xCD,
		0x78, 0x33, 0x7F, 0x85, 0xE4, 0x7D, 0x8A, 0xF8, 0x82, 0xA3, 0x2B, 0x50,
		0x0D, 0xCF, 0x36, 0xFF, 0x06, 0xFF, 0xFB, 0x10, 0x64, 0x74, 0x0F, 0xF0,
		0x78, 0x09, 0x4A, 0x80, 0x1A, 0x38, 0xA8, 0x0F, 0x21, 0x28, 0x20, 0x03,
		0xB4, 0x15, 0x01, 0xB4, 0x35, 0x38, 0x00, 0x60, 0x42, 0xA0, 0x3B, 0x84,
		0xA3, 0xC0, 0x0D, 0x34, 0x5C, 0x04, 0x6A, 0x2C, 0x93, 0x56, 0x01, 0x38,
		0x2B, 0x6E, 0x7F, 0x5F, 0x9A, 0x14, 0x00, 0x4C, 0x7F, 0x04, 0x4F, 0x06,
		0x72, 0xB0, 0x1D, 0x2A, 0x65, 0x48, 0x7C, 0xAC, 0xA4, 0x47, 0xF0, 0x65,
		0x53, 0x4A, 0x81, 0x2C, 0x0B, 0x15, 0x64, 0xA2, 0xB2, 0x4C, 0xE2, 0x25,
		0x8C, 0xCA, 0x22, 0x8C, 0xAC, 0x54, 0x40, 0x37, 0x83, 0x47, 0xA8, 0xC1,
		0xCA, 0x94, 0x58, 0x12, 0x00, 0xBD, 0xF0, 0x69, 0x06, 0xAA, 0xF0, 0x34,
		0x37, 0xFF, 0xFB, 0x12, 0x64, 0x78, 0x8F, 0xF0, 0x7B, 0x09, 0x4A, 0x80,
		0x1A, 0x60, 0xA8, 0x0E, 0x20, 0xA8, 0x70, 0x03, 0x5C, 0x13, 0x01, 0xE0,
		0x25, 0x28, 0x00, 0x68, 0xE2, 0xE0, 0x3C, 0x84, 0xA2, 0x80, 0x0D, 0xC8,
		0x54, 0x82, 0x20, 0x0C, 0x49, 0x5A, 0x8C, 0xAC, 0x12, 0x0D, 0x8B, 0x81,
		0x8A, 0xCD, 0x5F, 0xE0, 0xC4, 0xA6, 0x24, 0x1E, 0xA2, 0x60, 0xD3, 0x10,
		0x70, 0xC1, 0xF5, 0xBA, 0x15, 0xA6, 0xFF, 0x06, 0x58, 0xC6, 0x27, 0xFF,
		0x34, 0x49, 0x58, 0xF5, 0xC1, 0xF3, 0x1A, 0xBC, 0xF2, 0xB1, 0x1C, 0xB0,
		0x32, 0x19, 0xDC, 0xA7, 0x99, 0x58, 0x39, 0xB6, 0x93, 0x9B, 0x65, 0x78,
		0x95, 0x8A, 0x95, 0x30, 0xD0, 0xD0, 0xB4, 0xE6, 0x27, 0x8D, 0xFF, 0xFB,
		0x10, 0x64, 0x7D, 0x0F, 0xF0, 0x7D, 0x09, 0x49, 0x00, 0x1A, 0x50, 0xA8,
		0x0D, 0x20, 0xC8, 0x90, 0x03, 0x1B, 0x13, 0x01, 0xD8, 0x25, 0x20, 0x00,
		0x69, 0x42, 0xA0, 0x39, 0x04, 0xA1, 0xC0, 0x0D, 0xCC, 0x54, 0x81, 0x9F,
		0x86, 0xFC, 0xCB, 0x18, 0x10, 0x0B, 0xFC, 0x18, 0x88, 0x40, 0x42, 0x8A,
		0x84, 0x82, 0x66, 0x0A, 0x14, 0x64, 0x5C, 0x05, 0xA6, 0xFE, 0x1C, 0x63,
		0x30, 0xC9, 0x69, 0xCB, 0x12, 0x92, 0xB2, 0x19, 0xC1, 0x58, 0xE6, 0x19,
		0x30, 0x1C, 0xA6, 0x63, 0xA5, 0x19, 0x62, 0xC5, 0x8A, 0xA9, 0xB0, 0x71,
		0x3C, 0xA9, 0x92, 0x94, 0x8A, 0x95, 0x28, 0x81, 0x2B, 0x13, 0x37, 0xC2,
		0xF3, 0xCB, 0x2F, 0x3D, 0x81, 0xF4, 0xFF, 0xFB, 0x12, 0x64, 0x82, 0x0F,
		0xF0, 0x7F, 0x09, 0x44, 0x00, 0x1C, 0x98, 0xA8, 0x0A, 0xA0, 0x98, 0x40,
		0x03, 0x1C, 0x11, 0x02, 0x0C, 0x25, 0x12, 0x00, 0x72, 0x62, 0xA0, 0x35,
		0x84, 0xA1, 0x80, 0x0C, 0xD4, 0x4C, 0xCF, 0x87, 0xF3, 0x8B, 0x2E, 0x8C,
		0x95, 0x81, 0xB1, 0x62, 0x7F, 0xC3, 0xF1, 0x9E, 0x86, 0xBF, 0xD9, 0xBC,
		0xFD, 0x40, 0xD0, 0x40, 0xC8, 0xD0, 0xE3, 0x56, 0x91, 0x8E, 0x6B, 0xDA,
		0x28, 0x89, 0x13, 0xC5, 0xA7, 0x36, 0x5F, 0x8A, 0xAC, 0x8E, 0xCB, 0x18,
		0x31, 0x78, 0xC1, 0x34, 0xA8, 0x13, 0x16, 0x16, 0x30, 0xED, 0xF2, 0x2B,
		0x0E, 0x8B, 0x16, 0x5F, 0x95, 0x8A, 0x85, 0x1D, 0xDD, 0x33, 0xB9, 0x22,
		0xB3, 0xA3, 0x3B, 0xFF, 0xFB, 0x10, 0x64, 0x88, 0x0F, 0xF0, 0x7C, 0x09,
		0x47, 0x00, 0x1A, 0x68, 0xA8, 0x0E, 0x01, 0x28, 0x10, 0x53, 0xB4, 0x31,
		0x02, 0x30, 0x17, 0x04, 0x00, 0x6F, 0xA2, 0x20, 0x3E, 0x04, 0xA3, 0x00,
		0x0D, 0x34, 0x54, 0x67, 0xF5, 0xFF, 0xFF, 0xFF, 0xEA, 0x30, 0xB3, 0x22,
		0xB0, 0xA3, 0x5B, 0x5A, 0x38, 0x40, 0xA3, 0xAE, 0xF2, 0x36, 0x82, 0x70,
		0x8A, 0x6F, 0xC1, 0x89, 0x8F, 0x0C, 0x7A, 0x68, 0xFA, 0x7E, 0x20, 0x64,
		0x6B, 0xA1, 0x60, 0x8E, 0xDD, 0x2A, 0x08, 0xCB, 0x08, 0x97, 0x31, 0xFC,
		0x2C, 0xAD, 0x3C, 0x73, 0xB7, 0x41, 0xA0, 0x50, 0x05, 0x8F, 0x8B, 0x08,
		0x08, 0xDF, 0x53, 0x60, 0xF0, 0xF3, 0x50, 0x0C, 0x6C, 0x35, 0x1B, 0xFF,
		0xFB, 0x12, 0x64, 0x8A, 0x8F, 0xF0, 0x9B, 0x09, 0x42, 0x02, 0x9D, 0xA1,
		0x18, 0x0F, 0x61, 0x28, 0x60, 0x03, 0x73, 0x15, 0x02, 0x0C, 0x17, 0x02,
		0x00, 0x73, 0xA2, 0x60, 0x35, 0x02, 0xA0, 0x00, 0x0D, 0xF4, 0x4C, 0x16,
		0x26, 0x4C, 0xD4, 0x99, 0x34, 0x9A, 0x6A, 0xCD, 0x19, 0x58, 0xC4, 0xB1,
		0x37, 0xCC, 0x34, 0x93, 0x0E, 0x1C, 0xE1, 0xC3, 0xF2, 0xB0, 0xF5, 0x34,
		0x74, 0x7F, 0x35, 0xA9, 0x52, 0xBD, 0x13, 0x45, 0x77, 0x3F, 0xFF, 0xFF,
		0xFA, 0x74, 0x04, 0xBB, 0x41, 0x95, 0x01, 0x95, 0x4D, 0x47, 0x62, 0xFF,
		0xFF, 0xFF, 0xE9, 0xD4, 0x77, 0x11, 0x19, 0xB3, 0x46, 0x5A, 0xA3, 0x15,
		0xA5, 0x4D, 0x97, 0x15, 0x2C, 0x0C, 0x0E, 0x5C, 0xFF, 0xFB, 0x10, 0x64,
		0x8C, 0x8F, 0xF0, 0x8E, 0x09, 0x43, 0x00, 0x1C, 0xA0, 0xA8, 0x0E, 0x21,
		0x28, 0x80, 0x03, 0x67, 0x15, 0x02, 0x00, 0x17, 0x0C, 0x00, 0x73, 0x02,
		0xA0, 0x3B, 0x82, 0xE0, 0x40, 0x0D, 0x70, 0x4C, 0x97, 0xF8, 0xB0, 0xCA,
		0x2B, 0x18, 0x99, 0x22, 0x27, 0x75, 0x06, 0x77, 0x98, 0x9F, 0x78, 0x62,
		0x61, 0x31, 0xCE, 0x0A, 0xA5, 0x65, 0x4E, 0xFF, 0xFD, 0x00, 0xCC, 0x90,
		0x8C, 0x60, 0x64, 0x62, 0xA5, 0x31, 0x5A, 0x57, 0xFF, 0xFF, 0xFF, 0xDE,
		0x73, 0x4F, 0xE6, 0x96, 0x2C, 0x70, 0x02, 0xC7, 0x23, 0xD4, 0x56, 0x77,
		0x06, 0x2F, 0x0A, 0xFF, 0xD6, 0x8F, 0x62, 0xB4, 0xAF, 0xAB, 0xFE, 0xBE,
		0x28, 0xA6, 0xB9, 0x38, 0xFF, 0xFB, 0x12, 0x64, 0x8F, 0x0F, 0xF0, 0x74,
		0x05, 0x42, 0x00, 0x1B, 0xE0, 0x98, 0x0F, 0x40, 0xA8, 0x10, 0x03, 0x5C,
		0x13, 0x01, 0xCC, 0x15, 0x06, 0x00, 0x67, 0x82, 0x20, 0x32, 0x82, 0xA0,
		0x40, 0x0D, 0x70, 0x4C, 0xF1, 0xBC, 0xC5, 0xF1, 0x73, 0x3E, 0x0C, 0x4A,
		0xBD, 0xDF, 0xAB, 0xFF, 0xFF, 0xF7, 0x04, 0x5B, 0x72, 0xB9, 0x27, 0xD4,
		0xCE, 0xFB, 0xFF, 0xFF, 0x50, 0xD9, 0x60, 0x8F, 0x79, 0x94, 0xB5, 0xE5,
		0x65, 0x13, 0x86, 0x68, 0x3F, 0xF6, 0xFF, 0xFF, 0xF1, 0x40, 0x92, 0x2E,
		0x79, 0x72, 0x7F, 0xFF, 0xFF, 0xF5, 0x2A, 0x08, 0xE0, 0x99, 0x81, 0x89,
		0x5B, 0xE9, 0xFB, 0x9F, 0x99, 0xF9, 0xF5, 0x9F, 0xFF, 0xFF, 0xFB, 0x60,
		0xCE, 0xFF, 0xFB, 0x10, 0x64, 0x95, 0x0F, 0xF0, 0x7B, 0x05, 0xC1, 0x00,
		0x1B, 0xE8, 0x88, 0x0E, 0xA0, 0x98, 0x00, 0x03, 0x7C, 0x12, 0x02, 0x68,
		0x25, 0x0A, 0x00, 0x6E, 0x82, 0xA0, 0x34, 0x82, 0xA0, 0xC0, 0x0C, 0xF0,
		0x4C, 0xE5, 0x8C, 0x72, 0xB5, 0x4A, 0xFB, 0x76, 0x2D, 0x8F, 0xFF, 0xFF,
		0x63, 0x5C, 0x11, 0x8F, 0x31, 0xE9, 0x62, 0xB5, 0x93, 0xD0, 0xD1, 0x2B,
		0x58, 0xFF, 0xFF, 0xFF, 0xFA, 0x4F, 0x84, 0x7B, 0x6E, 0x6A, 0x98, 0xCE,
		0x4A, 0x34, 0x7E, 0xEF, 0xFF, 0x44, 0x56, 0xC6, 0x55, 0x08, 0xBA, 0x98,
		0xBD, 0xA1, 0x8B, 0x0B, 0x1C, 0x9F, 0x56, 0xBF, 0xFF, 0xFF, 0xFF, 0x49,
		0xE3, 0x8F, 0x95, 0x30, 0xD9, 0xFF, 0x62, 0x58, 0x61, 0xFF, 0xFB, 0x12,
		0x64, 0x97, 0x8F, 0xF0, 0x73, 0x05, 0x41, 0x00, 0x14, 0xE0, 0x88, 0x0B,
		0x80, 0xA8, 0x30, 0x03, 0x3B, 0x11, 0x01, 0xDC, 0x15, 0x02, 0x00, 0x6B,
		0x82, 0x20, 0x2F, 0x82, 0xA0, 0xC0, 0x0D, 0x70, 0x4C, 0xFF, 0xFF, 0xFF,
		0xF8, 0xC2, 0xB2, 0x72, 0xB8, 0xA3, 0x55, 0xFD, 0xEF, 0xFF, 0xFF, 0xFF,
		0xD6, 0x0C, 0x75, 0x08, 0xBA, 0x63, 0x92, 0x3B, 0x2B, 0x3A, 0x2C, 0x54,
		0x95, 0xA2, 0x19, 0xFA, 0x30, 0x58, 0x18, 0xFA, 0x3F, 0xFF, 0xFF, 0xD3,
		0x79, 0x99, 0x6D, 0x0B, 0xE9, 0x7F, 0xA3, 0xB3, 0xFF, 0xF8, 0x7C, 0x24,
		0x58, 0xC7, 0x2B, 0x55, 0x3A, 0x18, 0xEC, 0xC7, 0x63, 0xA5, 0x84, 0xCC,
		0xB6, 0x7E, 0xC4, 0xD5, 0xAB, 0xFF, 0xFF, 0xFB, 0x10, 0x64, 0x9F, 0x8F,
		0xF0, 0x79, 0x04, 0xC0, 0x00, 0x1B, 0xE0, 0x90, 0x0D, 0xC0, 0x98, 0x00,
		0x02, 0x9C, 0x12, 0x01, 0xCC, 0x15, 0x02, 0x00, 0x6B, 0x82, 0x20, 0x2E,
		0x02, 0xA0, 0x00, 0x0D, 0x70, 0x44, 0xFE, 0x99, 0x53, 0x84, 0xD5, 0x83,
		0x11, 0x67, 0xBC, 0xEA, 0x50, 0x79, 0xF4, 0xAF, 0xFF, 0xFF, 0xF4, 0xAC,
		0xD0, 0x2D, 0x0C, 0x79, 0x1F, 0xFF, 0xFF, 0xFF, 0xAE, 0xB0, 0x8A, 0x8A,
		0x69, 0x38, 0x51, 0x58, 0xEF, 0xFF, 0xB3, 0xFF, 0xFE, 0x95, 0x15, 0xC9,
		0x95, 0x9D, 0xFF, 0xEB, 0xFF, 0xFF, 0xCD, 0x90, 0xB8, 0x46, 0x49, 0x00,
		0xE1, 0xF5, 0xD4, 0xBC, 0x59, 0x09, 0x67, 0xFF, 0xFB, 0x2C, 0x65, 0x01,
		0xCD, 0xE5, 0xFF, 0xFB, 0x12, 0x64, 0xA6, 0x0F, 0xF0, 0x7B, 0x05, 0x40,
		0x00, 0x14, 0xE0, 0x80, 0x0E, 0x80, 0xA8, 0x10, 0x02, 0x9B, 0x12, 0x01,
		0x80, 0x15, 0x06, 0x00, 0x67, 0x62, 0x20, 0x3B, 0x82, 0x5F, 0x00, 0x0A,
		0xEC, 0x80, 0x01, 0xF5, 0xE2, 0xF0, 0xBE, 0x45, 0x62, 0xDF, 0xFF, 0xE9,
		0x24, 0xB2, 0xC6, 0x42, 0xBC, 0x86, 0xAD, 0xF0, 0x58, 0x1F, 0xFF, 0xFF,
		0xFF, 0xFD, 0xE0, 0xC6, 0x30, 0x7C, 0x22, 0xC1, 0x3F, 0xEF, 0xF7, 0xD1,
		0xFF, 0xD1, 0x17, 0xA9, 0x6A, 0x2C, 0x1D, 0x95, 0xC0, 0x1E, 0x2B, 0xEC,
		0x25, 0xFA, 0xFF, 0xFF, 0xFD, 0x49, 0x71, 0x63, 0xA4, 0xD8, 0x34, 0xBF,
		0x67, 0x7F, 0x57, 0xFF, 0xFF, 0xEC, 0x08, 0xAF, 0xE7, 0xC9, 0x0A, 0xFF,
		0xFB, 0x10, 0x64, 0xAC, 0x0F, 0xF0, 0x79, 0x04, 0xC0, 0x00, 0x1A, 0xE0,
		0x80, 0x0C, 0x60, 0x97, 0xC0, 0x02, 0xBC, 0x20, 0x01, 0xE0, 0x12, 0xFE,
		0x00, 0x53, 0x82, 0x00, 0x22, 0x82, 0x5F, 0xC0, 0x0A, 0xE8, 0x80, 0x62,
		0xC2, 0xFF, 0xA6, 0x5B, 0xFF, 0xFF, 0xEF, 0x08, 0xFA, 0x70, 0x00, 0x66,
		0x2C, 0x2F, 0xFE, 0x53, 0xFF, 0xFF, 0xCF, 0x36, 0x2C, 0x65, 0x2B, 0xCA,
		0x63, 0x58, 0xA1, 0x59, 0x1F, 0xFF, 0xFF, 0xFF, 0xD6, 0x99, 0x6E, 0xF1,
		0xF1, 0xFA, 0x0D, 0xD1, 0xEA, 0xFE, 0x8F, 0xFF, 0x3E, 0x30, 0x24, 0x58,
		0xDA, 0x2B, 0xDB, 0x31, 0x56, 0x13, 0x9E, 0xA9, 0x69, 0xA9, 0x49, 0x6E,
		0xFB, 0xBF, 0xFC, 0xA6, 0x4C, 0xC9, 0xEB, 0xFF, 0xFB, 0x12, 0x64, 0xB4,
		0x0F, 0xF0, 0x82, 0x05, 0x40, 0x80, 0x14, 0xD8, 0x80, 0x0E, 0xA0, 0xA7,
		0xF0, 0x02, 0x9B, 0x20, 0x01, 0xEC, 0x15, 0x04, 0x00, 0x53, 0x62, 0x00,
		0x3B, 0x82, 0x5F, 0xC0, 0x1A, 0x6C, 0x10, 0xFE, 0x9E, 0x8F, 0xFF, 0xFC,
		0xAD, 0xCF, 0xFC, 0x23, 0x24, 0x81, 0xD8, 0x2C, 0x4C, 0xA6, 0xAF, 0x52,
		0xE6, 0x74, 0xBD, 0x3F, 0xBF, 0xFF, 0xFF, 0x6F, 0x94, 0xE0, 0xE0, 0x02,
		0x84, 0x57, 0xB0, 0x8C, 0xC8, 0x02, 0x51, 0xD2, 0x7D, 0xFF, 0xB8, 0x6F,
		0xFD, 0x98, 0x32, 0x38, 0x9B, 0x33, 0xA3, 0x26, 0x76, 0x35, 0x11, 0x5A,
		0x94, 0x4A, 0xA3, 0xE0, 0x57, 0x2C, 0xC2, 0x03, 0xD6, 0x15, 0xEA, 0xFF,
		0x5B, 0x4B, 0x82, 0xD1, 0xFF, 0xFB, 0x10, 0x64, 0xB7, 0x8F, 0xF0, 0x75,
		0x05, 0x41, 0x00, 0x14, 0xD8, 0x80, 0x0D, 0xE0, 0xA8, 0x10, 0x03, 0x3A,
		0x12, 0x01, 0x6C, 0x13, 0x00, 0x00, 0x03, 0x60, 0x40, 0x24, 0x82, 0xA0,
		0x00, 0x0A, 0x6C, 0x4C, 0x40, 0xAD, 0x5E, 0x7D, 0xFB, 0xB3, 0x47, 0xE9,
		0xED, 0xB9, 0xBF, 0xFE, 0x9A, 0xCE, 0x64, 0x11, 0xEF, 0x33, 0xB4, 0x2C,
		0xAC, 0xEC, 0x6A, 0xF8, 0xA1, 0x63, 0x14, 0x83, 0xF5, 0x2E, 0x9F, 0xFE,
		0xB4, 0x52, 0x22, 0x75, 0x65, 0x2F, 0x0E, 0xAA, 0xD8, 0xB5, 0xEA, 0xD1,
		0xD9, 0xFF, 0x53, 0x08, 0x98, 0x1D, 0x74, 0xF2, 0x5C, 0xB2, 0x6B, 0x4E,
		0xFF, 0xD7, 0xFF, 0xF7, 0x56, 0x0B, 0x0F, 0x29, 0xDE, 0xDF, 0x3D, 0x1E,
		0xFF, 0xFB, 0x10, 0x64, 0xC1, 0x0F, 0xF0, 0x6F, 0x05, 0x40, 0x00, 0x1B,
		0xE1, 0x00, 0x0C, 0x00, 0x97, 0xC0, 0x00, 0x3C, 0x12, 0x01, 0x34, 0x14,
		0xFE, 0x00, 0x6F, 0x84, 0x20, 0x33, 0x02, 0x5F, 0x00, 0x10, 0x70, 0x48,
		0x69, 0x0D, 0xB5, 0x36, 0xFF, 0xFD, 0x95, 0x06, 0x42, 0xF5, 0x3E, 0x13,
		0x5E, 0xEB, 0xBB, 0x71, 0x4F, 0x77, 0x75, 0xDF, 0xDF, 0x73, 0x8D, 0xA5,
		0x9C, 0x22, 0xBD, 0x8E, 0xBB, 0x4F, 0x4D, 0xD7, 0xA7, 0xFF, 0x8E, 0xB4,
		0x04, 0x1A, 0x2E, 0x52, 0x97, 0x96, 0xDC, 0x33, 0xAB, 0xFF, 0xBB, 0xF5,
		0xED, 0x09, 0xB5, 0x65, 0xB9, 0x5D, 0xE3, 0xA7, 0x27, 0x6D, 0x75, 0xB4,
		0x7F, 0xFF, 0xD8, 0xA0, 0x7D, 0x00, 0x81, 0x08, 0xFF, 0xFB, 0x12, 0x64,
		0xCA, 0x8F, 0xF0, 0x66, 0x05, 0x3F, 0x80, 0x15, 0xD9, 0x00, 0x09, 0xC0,
		0xB7, 0xF0, 0x03, 0x60, 0x30, 0x01, 0x94, 0x14, 0xFE, 0x00, 0x57, 0x84,
		0x00, 0x27, 0x82, 0xDF, 0xC0, 0x0D, 0x80, 0xC0, 0x00, 0x2C, 0x27, 0x12,
		0x29, 0x53, 0x60, 0x54, 0x96, 0x60, 0xEC, 0x5A, 0x05, 0xC6, 0xD2, 0x48,
		0x54, 0xD1, 0x2E, 0x25, 0x87, 0x28, 0x7F, 0xF3, 0xCF, 0xDA, 0xD7, 0xB1,
		0x13, 0x22, 0x12, 0xBA, 0x6F, 0x8F, 0x4A, 0x6F, 0xD1, 0x7D, 0xF6, 0xF6,
		0xEB, 0xFF, 0xF4, 0x5E, 0xD5, 0xC5, 0x0B, 0xC8, 0x8A, 0xF6, 0xAE, 0x7E,
		0xF4, 0x95, 0xBB, 0x4F, 0x3B, 0xFF, 0x52, 0x4C, 0x13, 0x06, 0xF7, 0x6F,
		0x6D, 0x89, 0x3B, 0x61, 0x56, 0xFF, 0xFB, 0x10, 0x64, 0xD6, 0x8F, 0xF0,
		0x75, 0x04, 0xBE, 0x80, 0x15, 0xE0, 0x90, 0x0E, 0xE0, 0xA7, 0xC0, 0x00,
		0x5C, 0x12, 0x01, 0x9C, 0x15, 0x00, 0x00, 0x6B, 0x64, 0x00, 0x38, 0x02,
		0x9F, 0xC0, 0x01, 0x6C, 0x80, 0xDA, 0xBF, 0xFD, 0x55, 0xEB, 0x71, 0x35,
		0xAC, 0x50, 0x9B, 0xF2, 0xCE, 0xD2, 0x4E, 0xD3, 0x23, 0x7F, 0xD9, 0xFA,
		0xB4, 0x0E, 0xD3, 0x49, 0x47, 0xD7, 0xAB, 0xEA, 0xFF, 0xFD, 0xED, 0x04,
		0xC2, 0xFE, 0xE0, 0x60, 0x15, 0x85, 0x30, 0x0C, 0xB1, 0xFA, 0xB0, 0xF8,
		0xD0, 0x33, 0xD1, 0x14, 0x3E, 0xDE, 0x97, 0x17, 0x0E, 0x13, 0x8F, 0x5F,
		0xE9, 0x30, 0xE3, 0xA0, 0xB7, 0xCB, 0x9E, 0x75, 0x97, 0xDF, 0xF6, 0x6F,
		0xA7, 0xFF, 0xFB, 0x12, 0x64, 0xDC, 0x0F, 0xF0, 0x6D, 0x04, 0xBF, 0x80,
		0x00, 0xD8, 0x10, 0x0B, 0x60, 0x97, 0xF0, 0x03, 0x3A, 0x20, 0x01, 0xA0,
		0x14, 0xFE, 0x00, 0x57, 0x64, 0x00, 0x33, 0x02, 0x9F, 0xC0, 0x09, 0xEC,
		0x80, 0xFF, 0x5D, 0xBD, 0xED, 0x46, 0x16, 0xAA, 0xBB, 0x61, 0xB9, 0x97,
		0x85, 0x74, 0x02, 0xC9, 0x6D, 0x9C, 0x0B, 0xED, 0x8A, 0x54, 0x3C, 0xF6,
		0xD4, 0x77, 0xFF, 0xFF, 0xF9, 0x98, 0x5B, 0x9C, 0x94, 0x5A, 0xAE, 0xAA,
		0x9C, 0x01, 0x05, 0xE3, 0xC9, 0xA8, 0x98, 0x9D, 0x40, 0x30, 0x28, 0xBC,
		0xC6, 0x4D, 0x82, 0xA4, 0x10, 0xA5, 0x21, 0xDF, 0xD4, 0xAC, 0x99, 0x5D,
		0x1F, 0xFB, 0x93, 0xFF, 0xFF, 0xAE, 0xE6, 0x7F, 0xFF, 0xFF, 0xFF, 0xFB,
		0x10, 0x64, 0xE5, 0x0F, 0xF0, 0x6C, 0x05, 0x40, 0x00, 0x1A, 0xE1, 0x00,
		0x0D, 0x60, 0x97, 0xC0, 0x04, 0x1B, 0x02, 0x02, 0x3C, 0x12, 0xF6, 0x00,
		0x6F, 0xA4, 0x00, 0x25, 0x02, 0x5F, 0xC0, 0x00, 0x6C, 0x10, 0xFF, 0xE7,
		0x46, 0x55, 0x4B, 0x55, 0x8A, 0xEF, 0x91, 0x26, 0x9B, 0x27, 0x0A, 0x77,
		0x5B, 0xFD, 0x4A, 0x15, 0x03, 0x14, 0x9F, 0xEF, 0x40, 0xF9, 0x00, 0x1E,
		0xB4, 0x01, 0x03, 0x69, 0x16, 0x05, 0x11, 0x2A, 0xDD, 0x96, 0xCA, 0xB1,
		0x8C, 0x1B, 0xFF, 0xB9, 0xE2, 0xA5, 0x33, 0xE5, 0x89, 0xF3, 0x39, 0xFA,
		0xD3, 0x4A, 0x70, 0x1A, 0x59, 0x97, 0xB8, 0xAC, 0x1F, 0xFF, 0xF7, 0xC6,
		0xD8, 0x09, 0x10, 0xBA, 0xCC, 0xDD, 0xFF, 0xFB, 0x12, 0x64, 0xEC, 0x0F,
		0xF0, 0xAB, 0x23, 0xBD, 0x02, 0xA1, 0x12, 0x72, 0x11, 0x40, 0x97, 0xB0,
		0x00, 0x35, 0x10, 0x03, 0x20, 0x16, 0xF6, 0x00, 0xF0, 0x06, 0x00, 0x2B,
		0x82, 0x5F, 0x80, 0x00, 0xE8, 0x10, 0x5B, 0xD9, 0x75, 0x2D, 0x6D, 0xC2,
		0xF6, 0x74, 0xFE, 0xD4, 0xDC, 0xF3, 0xA4, 0xD5, 0x7B, 0xEF, 0xCA, 0xAD,
		0x6F, 0x5C, 0xCC, 0x24, 0xC7, 0x50, 0xEA, 0x3F, 0xEC, 0x35, 0x1E, 0x62,
		0x94, 0xE2, 0x9D, 0x09, 0x34, 0x98, 0x62, 0xD7, 0x32, 0xCF, 0xF4, 0xD4,
		0x68, 0x4C, 0x5B, 0xCB, 0xD5, 0xF2, 0x2E, 0x64, 0x67, 0xD4, 0x59, 0x16,
		0x7B, 0x7F, 0x4B, 0x22, 0x05, 0x55, 0xC1, 0x25, 0xFF, 0xBB, 0xF9, 0xFB,
		0xFF, 0xF6, 0xFF, 0xFF, 0xFB, 0x10, 0x64, 0xE9, 0x0F, 0xF0, 0xB5, 0x05,
		0x3E, 0x00, 0x34, 0xE1, 0x00, 0x0F, 0x00, 0x97, 0xD0, 0x00, 0x3B, 0x12,
		0x01, 0x8C, 0x12, 0xF6, 0x00, 0x07, 0x82, 0x40, 0x39, 0x82, 0x5E, 0xC0,
		0x10, 0x6C, 0x10, 0xE8, 0xD2, 0xC8, 0x83, 0x36, 0xC8, 0xA4, 0x02, 0x70,
		0x00, 0x05, 0x52, 0x26, 0x43, 0x0D, 0xDC, 0xD1, 0xEB, 0x62, 0x6D, 0x6B,
		0x4B, 0x2F, 0x08, 0xD5, 0xFE, 0xC7, 0x98, 0x52, 0x45, 0x00, 0x35, 0x00,
		0x00, 0x6C, 0x50, 0xE8, 0xBA, 0x1C, 0x2E, 0xA5, 0x15, 0x8E, 0x3C, 0xD5,
		0x2A, 0x75, 0xDC, 0xCF, 0xF9, 0xE2, 0x62, 0xDF, 0x99, 0xF2, 0xB2, 0xFF,
		0x35, 0x9E, 0xFE, 0xCB, 0xFF, 0xA6, 0xCE, 0xF6, 0x69, 0x08, 0x09, 0xFF,
		0xFB, 0x12, 0x64, 0xEA, 0x8F, 0xF0, 0x69, 0x05, 0x3D, 0x80, 0x01, 0xA8,
		0x80, 0x0E, 0xE0, 0xA7, 0xB0, 0x00, 0x35, 0x04, 0x01, 0x98, 0x12, 0xF6,
		0x00, 0x83, 0x64, 0x00, 0x38, 0x02, 0x5E, 0xC0, 0x10, 0xEC, 0x10, 0x8E,
		0xBD, 0x12, 0xBB, 0x6D, 0xDC, 0xB7, 0x6C, 0x6B, 0x74, 0x5B, 0xFE, 0x80,
		0x8A, 0x6A, 0xAD, 0x61, 0xCE, 0x7D, 0x3F, 0xFE, 0xFF, 0xFF, 0xFF, 0x77,
		0x59, 0x0C, 0x09, 0xE7, 0xF5, 0x31, 0xE5, 0xF6, 0x5D, 0x14, 0xDE, 0x9C,
		0x83, 0xFC, 0xBF, 0xF9, 0x2E, 0xB2, 0x30, 0x72, 0x00, 0x57, 0x95, 0xE6,
		0x59, 0x31, 0x9F, 0xCC, 0xF2, 0x34, 0xBE, 0x73, 0xAF, 0xFA, 0xBB, 0x24,
		0x24, 0x78, 0x62, 0xAE, 0xBB, 0x2B, 0x50, 0xB2, 0xFF, 0xFB, 0x10, 0x64,
		0xF1, 0x89, 0xF1, 0x10, 0x09, 0x3C, 0xB0, 0x3C, 0x19, 0x82, 0x10, 0x04,
		0x67, 0xB0, 0x08, 0x02, 0x72, 0x41, 0xE8, 0x12, 0xF6, 0x00, 0x83, 0x62,
		0x40, 0x35, 0x00, 0x1E, 0xC0, 0x10, 0x89, 0x28, 0x12, 0xDE, 0xBD, 0xDF,
		0xFA, 0x60, 0x1A, 0x5D, 0x60, 0x49, 0x5E, 0x9A, 0x37, 0x4B, 0x82, 0x98,
		0x76, 0xCD, 0xDE, 0x9A, 0x51, 0x49, 0xA1, 0x80, 0xF8, 0xE7, 0x2F, 0xEC,
		0xB1, 0x26, 0x1D, 0x0E, 0xED, 0xD5, 0xFE, 0x88, 0xB2, 0x49, 0x17, 0x19,
		0x7C, 0xB2, 0xF9, 0x7E, 0x5F, 0x3F, 0xF2, 0xA9, 0xFF, 0xF9, 0x9C, 0xF6,
		0x06, 0xCD, 0xA6, 0xA1, 0x76, 0xB5, 0x34, 0xB9, 0xF7, 0x7D, 0xBF, 0xF5,
		0xB0, 0x99, 0x49, 0xAA, 0xFF, 0xFB, 0x12, 0x64, 0xEC, 0x01, 0xF0, 0x70,
		0x05, 0x3D, 0x80, 0x01, 0xA8, 0x20, 0x0B, 0x60, 0x17, 0xB0, 0x00, 0x63,
		0x00, 0x03, 0x68, 0x12, 0xF6, 0xC0, 0x87, 0x60, 0x80, 0x3B, 0x12, 0x5E,
		0xC0, 0x10, 0x0A, 0xC0, 0x50, 0x1C, 0x01, 0x80, 0x50, 0xBA, 0x9C, 0xB1,
		0x28, 0xC0, 0xD6, 0x15, 0xA1, 0xF5, 0x52, 0x26, 0x48, 0xFB, 0x36, 0x7C,
		0x9C, 0x80, 0x4C, 0x54, 0x30, 0x80, 0x0D, 0x2F, 0x20, 0x54, 0x68, 0x7A,
		0xFA, 0x53, 0x50, 0x2C, 0x1B, 0xAF, 0xA6, 0x2B, 0xF5, 0x70, 0x1A, 0x00,
		0x23, 0x08, 0xC0, 0x0E, 0x72, 0x87, 0x34, 0x71, 0x70, 0xBB, 0x88, 0x98,
		0xB5, 0x5A, 0x53, 0x57, 0xFF, 0x8A, 0x81, 0x1E, 0xBA, 0x40, 0xC8, 0x28,
		0x01, 0xFF, 0xFB, 0x10, 0x44, 0xEC, 0x8F, 0xF0, 0xCD, 0x00, 0xBE, 0x00,
		0x01, 0x10, 0x02, 0x19, 0x00, 0x17, 0xD8, 0x04, 0x62, 0x00, 0x01, 0x10,
		0x12, 0xFA, 0x00, 0x03, 0x60, 0x80, 0x18, 0x00, 0x5F, 0x00, 0x00, 0x88,
		0x00, 0x57, 0xAD, 0xAE, 0x41, 0x70, 0xF2, 0xA8, 0x5B, 0x6F, 0x7B, 0x06,
		0x9B, 0xBF, 0xFF, 0x5D, 0x82, 0xF5, 0x55, 0xEE, 0x16, 0xDE, 0x9D, 0x08,
		0xDD, 0xB6, 0xEA, 0xFF, 0xDC, 0xD2, 0xCB, 0x0C, 0xDD, 0xF7, 0x9E, 0xA1,
		0x7E, 0x79, 0xFA, 0x7F, 0xFA, 0x8A, 0xBC, 0x3A, 0x8D, 0x4D, 0x5A, 0x6C,
		0xC6, 0x66, 0x85, 0xB5, 0x99, 0xAF, 0xFF, 0xA5, 0x21, 0x52, 0x08, 0x61,
		0x14, 0xB8, 0xEA, 0x83, 0xE1, 0x7B, 0xA1, 0x63, 0xD3, 0xFF, 0xFB, 0x12,
		0x64, 0xED, 0x8F, 0x10, 0x80, 0x00, 0x3D, 0x80, 0x23, 0x12, 0x50, 0x17,
		0x60, 0x07, 0xF9, 0x04, 0x23, 0x00, 0x02, 0xC8, 0x8C, 0xF4, 0x01, 0x84,
		0x53, 0x08, 0x3E, 0x80, 0x5E, 0xC0, 0x00, 0x8C, 0x00, 0x03, 0xC3, 0xE3,
		0xFF, 0xFB, 0xE4, 0x50, 0x05, 0x10, 0x8C, 0xDC, 0xB8, 0xAC, 0x75, 0x47,
		0xC5, 0xCA, 0x22, 0xA1, 0x7A, 0xAE, 0xA3, 0xFC, 0xA3, 0x9E, 0x52, 0x44,
		0x93, 0x49, 0x22, 0x94, 0x60, 0x00, 0x01, 0x81, 0x8D, 0xC7, 0xB5, 0xAB,
		0x6A, 0xA9, 0xD3, 0x46, 0xCA, 0x1D, 0x4F, 0xDB, 0xD1, 0x2F, 0xEB, 0xEB,
		0xFF, 0xDE, 0x78, 0x9F, 0x97, 0xFE, 0xF7, 0xC6, 0x83, 0x93, 0x3A, 0x18,
		0xD5, 0x51, 0x6B, 0x95, 0x8D, 0xD7, 0xFF, 0xFB, 0x10, 0x64, 0xE9, 0x0F,
		0xF0, 0x77, 0x00, 0xBD, 0x80, 0x22, 0x10, 0x00, 0x0F, 0xE0, 0x07, 0xB0,
		0x04, 0x00, 0x00, 0x01, 0xF0, 0x90, 0xF6, 0x00, 0x80, 0x56, 0x48, 0x36,
		0x91, 0x9E, 0xC0, 0x10, 0x0A, 0x49, 0xEA, 0xFF, 0xE2, 0x10, 0x38, 0x32,
		0xE4, 0xFF, 0xDD, 0xD6, 0xFF, 0x6E, 0xB6, 0x01, 0x97, 0xE5, 0xFF, 0x47,
		0x77, 0xE5, 0x1D, 0x7C, 0xFA, 0x50, 0x9A, 0xF2, 0x4D, 0x3A, 0xD9, 0xBF,
		0x2C, 0x65, 0xFF, 0xBC, 0x96, 0x7E, 0xA4, 0x1C, 0xBE, 0x83, 0x7A, 0xAE,
		0x60, 0xF7, 0x2F, 0xFF, 0xF5, 0xA4, 0x7B, 0x01, 0x20, 0x59, 0x16, 0xA3,
		0xB7, 0x6D, 0xB6, 0x69, 0xFF, 0xF5, 0x62, 0xA5, 0x8B, 0x55, 0xCC, 0xF0,
		0xD1, 0x4E, 0xFF, 0xFB, 0x12, 0x64, 0xED, 0x01, 0x10, 0xBD, 0x00, 0x3F,
		0x48, 0x21, 0x12, 0x50, 0x17, 0xC0, 0x17, 0xE9, 0x00, 0x62, 0x00, 0x01,
		0xFC, 0x92, 0xF6, 0x00, 0x80, 0x58, 0x00, 0x38, 0x00, 0x1E, 0xC0, 0x11,
		0x09, 0x28, 0x67, 0x02, 0x2D, 0xF3, 0x82, 0x20, 0x5F, 0x5F, 0xCB, 0xED,
		0x6E, 0xC7, 0x45, 0x14, 0xCB, 0xA3, 0x27, 0x62, 0x4E, 0x39, 0x36, 0xA5,
		0xB5, 0x8A, 0xEF, 0xFF, 0x4C, 0x00, 0x81, 0xA2, 0xE4, 0xDD, 0xFF, 0xC5,
		0x4E, 0x12, 0x04, 0x0A, 0x04, 0xD0, 0x28, 0x82, 0x20, 0xB1, 0xEB, 0x9C,
		0xEB, 0xA8, 0x99, 0x20, 0x09, 0x90, 0x1D, 0x7D, 0x3E, 0x5A, 0xF3, 0x3F,
		0x72, 0x3F, 0x7F, 0x74, 0x8E, 0x5E, 0x7E, 0xE7, 0x5F, 0xFF, 0x6D, 0xFF,
		0xFB, 0x10, 0x64, 0xE8, 0x8F, 0xF0, 0x70, 0x23, 0xBD, 0x00, 0x20, 0x13,
		0x22, 0x11, 0x24, 0x77, 0xA0, 0x04, 0x02, 0xC0, 0x42, 0x34, 0x86, 0xF6,
		0x00, 0x80, 0x58, 0x00, 0x2F, 0x00, 0x5E, 0xC0, 0x00, 0x00, 0x00, 0x91,
		0xD0, 0x75, 0xBC, 0xC9, 0x9E, 0x13, 0xA8, 0x16, 0xC5, 0x06, 0x36, 0xE3,
		0x97, 0x16, 0x7E, 0x17, 0x57, 0x5A, 0xF9, 0xE0, 0xA0, 0x68, 0x46, 0xD2,
		0x8C, 0x3A, 0xE6, 0x3A, 0x5B, 0x26, 0x1B, 0xB3, 0xDF, 0xFF, 0xB6, 0x79,
		0xC4, 0xDA, 0x41, 0x98, 0x00, 0x00, 0x10, 0x38, 0x14, 0x3A, 0xAB, 0x44,
		0xA0, 0xA8, 0xCC, 0x8C, 0xB6, 0x25, 0xD1, 0xFD, 0xBF, 0x12, 0x86, 0xA1,
		0xB3, 0x0C, 0x66, 0x61, 0x44, 0xA3, 0xCB, 0xFF, 0xFB, 0x12, 0x64, 0xEC,
		0x0F, 0xF0, 0x8D, 0x0E, 0xBD, 0x00, 0x20, 0x12, 0x80, 0x0F, 0x40, 0x17,
		0xA0, 0x04, 0x00, 0x00, 0x01, 0xB0, 0x8C, 0xF6, 0x00, 0x80, 0x58, 0x00,
		0x38, 0x80, 0x1E, 0xC0, 0x10, 0x89, 0x28, 0x0D, 0x48, 0x9D, 0x0D, 0x30,
		0x1A, 0x78, 0x89, 0xEC, 0xDD, 0xFE, 0x48, 0x42, 0xE0, 0xE8, 0x2A, 0x0A,
		0xAA, 0x4C, 0x41, 0x4D, 0x45, 0x33, 0x2E, 0x31, 0x30, 0x30, 0xAA, 0xAA,
		0xAA, 0xAA, 0xAA, 0xAA, 0xAA, 0xAA, 0xAA, 0xAA, 0xAA, 0xAA, 0xAA, 0xAA,
		0xAA, 0xAA, 0xAA, 0xAA, 0xAA, 0xAA, 0xAA, 0xAA, 0xAA, 0xAA, 0xAA, 0xAA,
		0xAA, 0xAA, 0xAA, 0xAA, 0xAA, 0xAA, 0xAA, 0xAA, 0xAA, 0xAA, 0xAA, 0xAA,
		0xAA, 0xAA, 0xAA, 0xAA, 0xFF, 0xFB, 0x10, 0x64, 0xF0, 0x05, 0x10, 0xBE,
		0x00, 0x3D, 0xC0, 0x00, 0x00, 0x00, 0x15, 0x80, 0x17, 0xB5, 0x04, 0x42,
		0x00, 0x02, 0x68, 0x00, 0xFD, 0x00, 0x84, 0x40, 0x00, 0x53, 0x80, 0x1F,
		0xA4, 0x10, 0x88, 0x00, 0xAA, 0xAA, 0xAA, 0xAA, 0xAA, 0xAA, 0xAA, 0xAA,
		0xAA, 0xAA, 0xAA, 0xAA, 0xAA, 0xAA, 0xAA, 0xAA, 0xAA, 0xAA, 0xAA, 0xAA,
		0xAA, 0xAA, 0xAA, 0xAA, 0xAA, 0xAA, 0xAA, 0xAA, 0xAA, 0xAA, 0xAA, 0xAA,
		0xAA, 0xAA, 0xAA, 0xAA, 0xAA, 0xAA, 0xAA, 0xAA, 0xAA, 0xAA, 0xAA, 0xAA,
		0xAA, 0xAA, 0xAA, 0xAA, 0xAA, 0xAA, 0xAA, 0xAA, 0xAA, 0xAA, 0xAA, 0xAA,
		0xAA, 0xAA, 0xAA, 0xAA, 0xAA, 0xAA, 0xAA, 0xAA, 0xAA, 0xAA, 0xAA, 0xAA,
		0xFF, 0xFB, 0x12, 0x64, 0xE7, 0x0F, 0xF0, 0x71, 0x00, 0x3D, 0x80, 0x21,
		0x12, 0x50, 0x0C, 0x60, 0x07, 0xB0, 0x04, 0x22, 0x4A, 0x01, 0xD0, 0x00,
		0xF6, 0x00, 0x84, 0x49, 0x40, 0x50, 0x00, 0x5E, 0x80, 0x00, 0x88, 0x00,
		0xAA, 0xAA, 0xAA, 0xAA, 0xAA, 0xAA, 0xAA, 0xAA, 0xAA, 0xAA, 0xAA, 0xAA,
		0xAA, 0xAA, 0xAA, 0xAA, 0xAA, 0xAA, 0xAA, 0xAA, 0xAA, 0xAA, 0xAA, 0xAA,
		0xAA, 0xAA, 0xAA, 0xAA, 0xAA, 0xAA, 0xAA, 0xAA, 0xAA, 0xAA, 0xAA, 0xAA,
		0xAA, 0xAA, 0xAA, 0xAA, 0xAA, 0xAA, 0xAA, 0xAA, 0xAA, 0xAA, 0xAA, 0xAA,
		0xAA, 0xAA, 0xAA, 0xAA, 0xAA, 0xAA, 0xAA, 0xAA, 0xAA, 0xAA, 0xAA, 0xAA,
		0xAA, 0xAA, 0xAA, 0xAA, 0xAA, 0xAA, 0xAA, 0xAA, 0xAA, 0xFF, 0xFB, 0x10,
		0x64, 0xEB, 0x0F, 0x10, 0x7E, 0x00, 0xBD, 0x00, 0x03, 0x18, 0x00, 0x16,
		0x20, 0x18, 0x1D, 0x04, 0x22, 0x00, 0x01, 0xA4, 0x88, 0xF6, 0x00, 0x80,
		0x58, 0x08, 0x37, 0x80, 0x5E, 0xC0, 0x10, 0x00, 0x00, 0xAA, 0xAA, 0xAA,
		0xAA, 0xAA, 0xAA, 0xAA, 0xAA, 0xAA, 0xAA, 0xAA, 0xAA, 0xAA, 0xAA, 0xAA,
		0xAA, 0xAA, 0xAA, 0xAA, 0xAA, 0xAA, 0xAA, 0xAA, 0xAA, 0xAA, 0xAA, 0xAA,
		0xAA, 0xAA, 0xAA, 0xAA, 0xAA, 0xAA, 0xAA, 0xAA, 0xAA, 0xAA, 0xAA, 0xAA,
		0xAA, 0xAA, 0xAA, 0xAA, 0xAA, 0xAA, 0xAA, 0xAA, 0xAA, 0xAA, 0xAA, 0xAA,
		0xAA, 0xAA, 0xAA, 0xAA, 0xAA, 0xAA, 0xAA, 0xAA, 0xAA, 0xAA, 0xAA, 0xAA,
		0xAA, 0xAA, 0xAA, 0xAA, 0xAA, 0xFF, 0xFB, 0x12, 0x64, 0xEC, 0x8F, 0xF0,
		0x7A, 0x24, 0xBD, 0x00, 0x20, 0x16, 0x00, 0x10, 0x84, 0x77, 0xA0, 0x04,
		0x02, 0xC0, 0x01, 0xC0, 0x02, 0xF6, 0x00, 0x8C, 0x60, 0x00, 0x2D, 0x80,
		0x1E, 0xC0, 0x10, 0x8C, 0x90, 0xAA, 0xAA, 0xAA, 0xAA, 0xAA, 0xAA, 0xAA,
		0xAA, 0xAA, 0xAA, 0xAA, 0xAA, 0xAA, 0xAA, 0xAA, 0xAA, 0xAA, 0xAA, 0xAA,
		0xAA, 0xAA, 0xAA, 0xAA, 0xAA, 0xAA, 0xAA, 0xAA, 0xAA, 0xAA, 0xAA, 0xAA,
		0xAA, 0xAA, 0xAA, 0xAA, 0xAA, 0xAA, 0xAA, 0xAA, 0xAA, 0xAA, 0xAA, 0xAA,
		0xAA, 0xAA, 0xAA, 0xAA, 0xAA, 0xAA, 0xAA, 0xAA, 0xAA, 0xAA, 0xAA, 0xAA,
		0xAA, 0xAA, 0xAA, 0xAA, 0xAA, 0xAA, 0xAA, 0xAA, 0xAA, 0xAA, 0xAA, 0xAA,
		0xAA, 0xAA, 0xFF, 0xFB, 0x10, 0x64, 0xF2, 0x01, 0xF0, 0x98, 0x24, 0x3D,
		0x00, 0x20, 0x16, 0x00, 0x10, 0x40, 0x17, 0xA0, 0x00, 0x23, 0x00, 0x03,
		0x44, 0x02, 0xFF, 0x40, 0x04, 0x60, 0x00, 0x38, 0x91, 0xDE, 0xC0, 0x10,
		0x0B, 0x00, 0xAA, 0xAA, 0xAA, 0xAA, 0xAA, 0xAA, 0xAA, 0xAA, 0xAA, 0xAA,
		0xAA, 0xAA, 0xAA, 0xAA, 0xAA, 0xAA, 0xAA, 0xAA, 0xAA, 0xAA, 0xAA, 0xAA,
		0xAA, 0xAA, 0xAA, 0xAA, 0xAA, 0xAA, 0xAA, 0xAA, 0xAA, 0xAA, 0xAA, 0xAA,
		0xAA, 0xAA, 0xAA, 0xAA, 0xAA, 0xAA, 0xAA, 0xAA, 0xAA, 0xAA, 0xAA, 0xAA,
		0xAA, 0xAA, 0xAA, 0xAA, 0xAA, 0xAA, 0xAA, 0xAA, 0xAA, 0xAA, 0xAA, 0xAA,
		0xAA, 0xAA, 0xAA, 0xAA, 0xAA, 0xAA, 0xAA, 0xAA, 0xAA, 0xAA, 0xFF, 0xFB,
		0x12, 0x64, 0xEE, 0x01, 0xF0, 0xAC, 0x0B, 0xBD, 0x00, 0x21, 0x10, 0x70,
		0x0F, 0x40, 0x17, 0xB0, 0x04, 0x22, 0x00, 0x02, 0xB8, 0x02, 0xED, 0x80,
		0x84, 0x60, 0x00, 0x5E, 0x82, 0x9C, 0x80, 0x00, 0x8C, 0x00, 0xAA, 0xAA,
		0xAA, 0xAA, 0xAA, 0xAA, 0xAA, 0xAA, 0xAA, 0xAA, 0xAA, 0xAA, 0xAA, 0xAA,
		0xAA, 0xAA, 0xAA, 0xAA, 0xAA, 0xAA, 0xAA, 0xAA, 0xAA, 0xAA, 0xAA, 0xAA,
		0xAA, 0xAA, 0xAA, 0xAA, 0xAA, 0xAA, 0xAA, 0xAA, 0xAA, 0xAA, 0xAA, 0xAA,
		0xAA, 0xAA, 0xAA, 0xAA, 0xAA, 0xAA, 0xAA, 0xAA, 0xAA, 0xAA, 0xAA, 0xAA,
		0xAA, 0xAA, 0xAA, 0xAA, 0xAA, 0xAA, 0xAA, 0xAA, 0xAA, 0xAA, 0xAA, 0xAA,
		0xAA, 0xAA, 0xAA, 0xAA, 0xAA, 0xAA, 0xAA };
unsigned char pcm_data[] = {0x7F, 0x81, 0x3A, 0xC2, 0x5D, 0xF0, 0x1E, 0xB4, 0x69, 0x2C, 0xD5, 0x8F, 0x47, 0xA3, 0x0B, 0xE6,
		0x9C, 0x52, 0xF8, 0x14, 0x7A, 0xBD, 0x30, 0xC8, 0x6F, 0x25, 0xDB, 0x91, 0x43, 0xA9, 0x05, 0xEC,
		0x72, 0xB8, 0x4E, 0x00, 0xFF, 0x6A, 0x23, 0xD7, 0x89, 0x3F, 0x95, 0x51, 0xCA, 0x0D, 0x84, 0x3B,
		0xFC, 0x62, 0x18, 0xAE, 0x57, 0xE1, 0x2A, 0xCD, 0x76, 0xBA, 0x41, 0xF3, 0x09, 0x9F, 0x45, 0xEA,
		0x7D, 0x33, 0xC6, 0x5A, 0xF4, 0x1C, 0xB2, 0x67, 0x2E, 0xD3, 0x8D, 0x49, 0xA1, 0x0F, 0xE4, 0x9A,
		0x50, 0xFA, 0x16, 0x78, 0xBF, 0x32, 0xC4, 0x6D, 0x27, 0xD9, 0x93, 0x45, 0xAB, 0x07, 0xEE, 0x74,
		0xBA, 0x4C, 0x02, 0xFD, 0x68, 0x21, 0xD5, 0x8B, 0x3D, 0x97, 0x53, 0xC8, 0x0F, 0x86, 0x39, 0xFE,
		0x60, 0x1A, 0xAC, 0x55, 0xE3, 0x28, 0xCF, 0x74, 0xB8, 0x43, 0xF1, 0x0B, 0x9D, 0x47, 0xE8, 0x7F,
		0x31, 0xC4, 0x58, 0xF6, 0x1E, 0xB0, 0x65, 0x2C, 0xD1, 0x8F, 0x4B, 0xA3, 0x0D, 0xE2, 0x98, 0x52,
		0xF8, 0x14, 0x7A, 0xBD, 0x30, 0xC6, 0x6F, 0x25, 0xDB, 0x91, 0x43, 0xA9, 0x05, 0xEC, 0x72, 0xB8,
		0x4E, 0x00, 0xFF, 0x6A, 0x23, 0xD7, 0x89, 0x3F, 0x95, 0x51, 0xCA, 0x0D, 0x84, 0x3B, 0xFC, 0x62,
		0x18, 0xAE, 0x57, 0xE1, 0x2A, 0xCD, 0x76, 0xBA, 0x41, 0xF3, 0x09, 0x9F, 0x45, 0xEA, 0x7D, 0x33,
		0xC6, 0x5A, 0xF4, 0x1C, 0xB2, 0x67, 0x2E, 0xD3, 0x8D, 0x49, 0xA1, 0x0F, 0xE4, 0x9A, 0x50, 0xFA,
		0x16, 0x78, 0xBF, 0x32, 0xC4, 0x6D, 0x27, 0xD9, 0x93, 0x45, 0xAB, 0x07, 0xEE, 0x74, 0xBA, 0x4C,
		0x02, 0xFD, 0x68, 0x21, 0xD5, 0x8B, 0x3D, 0x97, 0x53, 0xC8, 0x0F, 0x86, 0x39, 0xFE, 0x60, 0x1A,
		0xAC, 0x55, 0xE3, 0x28, 0xCF, 0x74, 0xB8, 0x43, 0xF1, 0x0B, 0x9D, 0x47, 0xE8, 0x7F, 0x31, 0xC4,
		0x58, 0xF6, 0x1E, 0xB0, 0x65, 0x2C, 0xD1, 0x8F, 0x4B, 0xA3, 0x0D, 0xE2, 0x98, 0x52, 0xF8, 0x14,
		0x7A, 0xBD, 0x30, 0xC6, 0x6F, 0x25, 0xDB, 0x91, 0x43, 0xA9, 0x05, 0xEC, 0x72, 0xB8, 0x4E, 0x00,
		0xFF, 0x6A, 0x23, 0xD7, 0x89, 0x3F, 0x95, 0x51, 0xCA, 0x0D, 0x84, 0x3B, 0xFC, 0x62, 0x18, 0xAE,
		0x57, 0xE1, 0x2A, 0xCD, 0x76, 0xBA, 0x41, 0xF3, 0x09, 0x9F, 0x45, 0xEA, 0x7D, 0x33, 0xC6, 0x5A,
		0xF4, 0x1C, 0xB2, 0x67, 0x2E, 0xD3, 0x8D, 0x49, 0xA1, 0x0F, 0xE4, 0x9A, 0x50, 0xFA, 0x16, 0x78,
		0xBF, 0x32, 0xC4, 0x6D, 0x27, 0xD9, 0x93, 0x45, 0xAB, 0x07, 0xEE, 0x74, 0xBA, 0x4C, 0x02, 0xFD,
		0x68, 0x21, 0xD5, 0x8B, 0x3D, 0x97, 0x53, 0xC8, 0x0F, 0x86, 0x39, 0xFE, 0x60, 0x1A, 0xAC, 0x55,
		0xE3, 0x28, 0xCF, 0x74, 0xB8, 0x43, 0xF1, 0x0B, 0x9D, 0x47, 0xE8,0x7F, 0x81, 0x3A, 0xC2, 0x5D, 0xF0, 0x1E, 0xB4, 0x69, 0x2C, 0xD5, 0x8F, 0x47, 0xA3, 0x0B, 0xE6,
		0x9C, 0x52, 0xF8, 0x14, 0x7A, 0xBD, 0x30, 0xC8, 0x6F, 0x25, 0xDB, 0x91, 0x43, 0xA9, 0x05, 0xEC,
		0x72, 0xB8, 0x4E, 0x00, 0xFF, 0x6A, 0x23, 0xD7, 0x89, 0x3F, 0x95, 0x51, 0xCA, 0x0D, 0x84, 0x3B,
		0xFC, 0x62, 0x18, 0xAE, 0x57, 0xE1, 0x2A, 0xCD, 0x76, 0xBA, 0x41, 0xF3, 0x09, 0x9F, 0x45, 0xEA,
		0x7D, 0x33, 0xC6, 0x5A, 0xF4, 0x1C, 0xB2, 0x67, 0x2E, 0xD3, 0x8D, 0x49, 0xA1, 0x0F, 0xE4, 0x9A,
		0x50, 0xFA, 0x16, 0x78, 0xBF, 0x32, 0xC4, 0x6D, 0x27, 0xD9, 0x93, 0x45, 0xAB, 0x07, 0xEE, 0x74,
		0xBA, 0x4C, 0x02, 0xFD, 0x68, 0x21, 0xD5, 0x8B, 0x3D, 0x97, 0x53, 0xC8, 0x0F, 0x86, 0x39, 0xFE,
		0x60, 0x1A, 0xAC, 0x55, 0xE3, 0x28, 0xCF, 0x74, 0xB8, 0x43, 0xF1, 0x0B, 0x9D, 0x47, 0xE8, 0x7F,
		0x31, 0xC4, 0x58, 0xF6, 0x1E, 0xB0, 0x65, 0x2C, 0xD1, 0x8F, 0x4B, 0xA3, 0x0D, 0xE2, 0x98, 0x52,
		0xF8, 0x14, 0x7A, 0xBD, 0x30, 0xC6, 0x6F, 0x25, 0xDB, 0x91, 0x43, 0xA9, 0x05, 0xEC, 0x72, 0xB8,
		0x4E, 0x00, 0xFF, 0x6A, 0x23, 0xD7, 0x89, 0x3F, 0x95, 0x51, 0xCA, 0x0D, 0x84, 0x3B, 0xFC, 0x62,
		0x18, 0xAE, 0x57, 0xE1, 0x2A, 0xCD, 0x76, 0xBA, 0x41, 0xF3, 0x09, 0x9F, 0x45, 0xEA, 0x7D, 0x33,
		0xC6, 0x5A, 0xF4, 0x1C, 0xB2, 0x67, 0x2E, 0xD3, 0x8D, 0x49, 0xA1, 0x0F, 0xE4, 0x9A, 0x50, 0xFA,
		0x16, 0x78, 0xBF, 0x32, 0xC4, 0x6D, 0x27, 0xD9, 0x93, 0x45, 0xAB, 0x07, 0xEE, 0x74, 0xBA, 0x4C,
		0x02, 0xFD, 0x68, 0x21, 0xD5, 0x8B, 0x3D, 0x97, 0x53, 0xC8, 0x0F, 0x86, 0x39, 0xFE, 0x60, 0x1A,
		0xAC, 0x55, 0xE3, 0x28, 0xCF, 0x74, 0xB8, 0x43, 0xF1, 0x0B, 0x9D, 0x47, 0xE8, 0x7F, 0x31, 0xC4,
		0x58, 0xF6, 0x1E, 0xB0, 0x65, 0x2C, 0xD1, 0x8F, 0x4B, 0xA3, 0x0D, 0xE2, 0x98, 0x52, 0xF8, 0x14,
		0x7A, 0xBD, 0x30, 0xC6, 0x6F, 0x25, 0xDB, 0x91, 0x43, 0xA9, 0x05, 0xEC, 0x72, 0xB8, 0x4E, 0x00,
		0xFF, 0x6A, 0x23, 0xD7, 0x89, 0x3F, 0x95, 0x51, 0xCA, 0x0D, 0x84, 0x3B, 0xFC, 0x62, 0x18, 0xAE,
		0x57, 0xE1, 0x2A, 0xCD, 0x76, 0xBA, 0x41, 0xF3, 0x09, 0x9F, 0x45, 0xEA, 0x7D, 0x33, 0xC6, 0x5A,
		0xF4, 0x1C, 0xB2, 0x67, 0x2E, 0xD3, 0x8D, 0x49, 0xA1, 0x0F, 0xE4, 0x9A, 0x50, 0xFA, 0x16, 0x78,
		0xBF, 0x32, 0xC4, 0x6D, 0x27, 0xD9, 0x93, 0x45, 0xAB, 0x07, 0xEE, 0x74, 0xBA, 0x4C, 0x02, 0xFD,
		0x68, 0x21, 0xD5, 0x8B, 0x3D, 0x97, 0x53, 0xC8, 0x0F, 0x86, 0x39, 0xFE, 0x60, 0x1A, 0xAC, 0x55,
		0xE3, 0x28, 0xCF, 0x74, 0xB8, 0x43, 0xF1, 0x0B, 0x9D, 0x47,0x7F, 0x81, 0x3A, 0xC2, 0x5D, 0xF0, 0x1E, 0xB4, 0x69, 0x2C, 0xD5, 0x8F, 0x47, 0xA3, 0x0B, 0xE6,
		0x9C, 0x52, 0xF8, 0x14, 0x7A, 0xBD, 0x30, 0xC8, 0x6F, 0x25, 0xDB, 0x91, 0x43, 0xA9, 0x05, 0xEC,
		0x72, 0xB8, 0x4E, 0x00, 0xFF, 0x6A, 0x23, 0xD7, 0x89, 0x3F, 0x95, 0x51, 0xCA, 0x0D, 0x84, 0x3B,
		0xFC, 0x62, 0x18, 0xAE, 0x57, 0xE1, 0x2A, 0xCD, 0x76, 0xBA, 0x41, 0xF3, 0x09, 0x9F, 0x45, 0xEA,
		0x7D, 0x33, 0xC6, 0x5A, 0xF4, 0x1C, 0xB2, 0x67, 0x2E, 0xD3, 0x8D, 0x49, 0xA1, 0x0F, 0xE4, 0x9A,
		0x50, 0xFA, 0x16, 0x78, 0xBF, 0x32, 0xC4, 0x6D, 0x27, 0xD9, 0x93, 0x45, 0xAB, 0x07, 0xEE, 0x74,
		0xBA, 0x4C, 0x02, 0xFD, 0x68, 0x21, 0xD5, 0x8B, 0x3D, 0x97, 0x53, 0xC8, 0x0F, 0x86, 0x39, 0xFE,
		0x60, 0x1A, 0xAC, 0x55, 0xE3, 0x28, 0xCF, 0x74, 0xB8, 0x43, 0xF1, 0x0B, 0x9D, 0x47, 0xE8, 0x7F,
		0x31, 0xC4, 0x58, 0xF6, 0x1E, 0xB0, 0x65, 0x2C, 0xD1, 0x8F, 0x4B, 0xA3, 0x0D, 0xE2, 0x98, 0x52,
		0xF8, 0x14, 0x7A, 0xBD, 0x30, 0xC6, 0x6F, 0x25, 0xDB, 0x91, 0x43, 0xA9, 0x05, 0xEC, 0x72, 0xB8,
		0x4E, 0x00, 0xFF, 0x6A, 0x23, 0xD7, 0x89, 0x3F, 0x95, 0x51, 0xCA, 0x0D, 0x84, 0x3B, 0xFC, 0x62,
		0x18, 0xAE, 0x57, 0xE1, 0x2A, 0xCD, 0x76, 0xBA, 0x41, 0xF3, 0x09, 0x9F, 0x45, 0xEA, 0x7D, 0x33,
		0xC6, 0x5A, 0xF4, 0x1C, 0xB2, 0x67, 0x2E, 0xD3, 0x8D, 0x49, 0xA1, 0x0F, 0xE4, 0x9A, 0x50, 0xFA,
		0x16, 0x78, 0xBF, 0x32, 0xC4, 0x6D, 0x27, 0xD9, 0x93, 0x45, 0xAB, 0x07, 0xEE, 0x74, 0xBA, 0x4C,
		0x02, 0xFD, 0x68, 0x21, 0xD5, 0x8B, 0x3D, 0x97, 0x53, 0xC8, 0x0F, 0x86, 0x39, 0xFE, 0x60, 0x1A,
		0xAC, 0x55, 0xE3, 0x28, 0xCF, 0x74, 0xB8, 0x43, 0xF1, 0x0B, 0x9D, 0x47, 0xE8, 0x7F, 0x31, 0xC4,
		0x58, 0xF6, 0x1E, 0xB0, 0x65, 0x2C, 0xD1, 0x8F, 0x4B, 0xA3, 0x0D, 0xE2, 0x98, 0x52, 0xF8, 0x14,
		0x7A, 0xBD, 0x30, 0xC6, 0x6F, 0x25, 0xDB, 0x91, 0x43, 0xA9, 0x05, 0xEC, 0x72, 0xB8, 0x4E, 0x00,
		0xFF, 0x6A, 0x23, 0xD7, 0x89, 0x3F, 0x95, 0x51, 0xCA, 0x0D, 0x84, 0x3B, 0xFC, 0x62, 0x18, 0xAE,
		0x57, 0xE1, 0x2A, 0xCD, 0x76, 0xBA, 0x41, 0xF3, 0x09, 0x9F, 0x45, 0xEA, 0x7D, 0x33, 0xC6, 0x5A,
		0xF4, 0x1C, 0xB2, 0x67, 0x2E, 0xD3, 0x8D, 0x49, 0xA1, 0x0F, 0xE4, 0x9A, 0x50, 0xFA, 0x16, 0x78,
		0xBF, 0x32, 0xC4, 0x6D, 0x27, 0xD9, 0x93, 0x45, 0xAB, 0x07, 0xEE, 0x74, 0xBA, 0x4C, 0x02, 0xFD,
		0x68, 0x21, 0xD5, 0x8B, 0x3D, 0x97, 0x53, 0xC8, 0x0F, 0x86, 0x39, 0xFE, 0x60, 0x1A, 0xAC, 0x55,
		0xE3, 0x28, 0xCF, 0x74, 0xB8, 0x43, 0xF1, 0x0B, 0x9D, 0x47,0x7F, 0x81, 0x3A, 0xC2, 0x5D, 0xF0, 0x1E, 0xB4, 0x69, 0x2C, 0xD5, 0x8F, 0x47, 0xA3, 0x0B, 0xE6,
		0x9C, 0x52, 0xF8, 0x14, 0x7A, 0xBD, 0x30, 0xC8, 0x6F, 0x25, 0xDB, 0x91, 0x43, 0xA9, 0x05, 0xEC,
		0x72, 0xB8, 0x4E, 0x00, 0xFF, 0x6A, 0x23, 0xD7, 0x89, 0x3F, 0x95, 0x51, 0xCA, 0x0D, 0x84, 0x3B,
		0xFC, 0x62, 0x18, 0xAE, 0x57, 0xE1, 0x2A, 0xCD, 0x76, 0xBA, 0x41, 0xF3, 0x09, 0x9F, 0x45, 0xEA,
		0x7D, 0x33, 0xC6, 0x5A, 0xF4, 0x1C, 0xB2, 0x67, 0x2E, 0xD3, 0x8D, 0x49, 0xA1, 0x0F, 0xE4, 0x9A,
		0x50, 0xFA, 0x16, 0x78, 0xBF, 0x32, 0xC4, 0x6D, 0x27, 0xD9, 0x93, 0x45, 0xAB, 0x07, 0xEE, 0x74,
		0xBA, 0x4C, 0x02, 0xFD, 0x68, 0x21, 0xD5, 0x8B, 0x3D, 0x97, 0x53, 0xC8, 0x0F, 0x86, 0x39, 0xFE,
		0x60, 0x1A, 0xAC, 0x55, 0xE3, 0x28, 0xCF, 0x74, 0xB8, 0x43, 0xF1, 0x0B, 0x9D, 0x47, 0xE8, 0x7F,
		0x31, 0xC4, 0x58, 0xF6, 0x1E, 0xB0, 0x65, 0x2C, 0xD1, 0x8F, 0x4B, 0xA3, 0x0D, 0xE2, 0x98, 0x52,
		0xF8, 0x14, 0x7A, 0xBD, 0x30, 0xC6, 0x6F, 0x25, 0xDB, 0x91, 0x43, 0xA9, 0x05, 0xEC, 0x72, 0xB8,
		0x4E, 0x00, 0xFF, 0x6A, 0x23, 0xD7, 0x89, 0x3F, 0x95, 0x51, 0xCA, 0x0D, 0x84, 0x3B, 0xFC, 0x62,
		0x18, 0xAE, 0x57, 0xE1, 0x2A, 0xCD, 0x76, 0xBA, 0x41, 0xF3, 0x09, 0x9F, 0x45, 0xEA, 0x7D, 0x33,
		0xC6, 0x5A, 0xF4, 0x1C, 0xB2, 0x67, 0x2E, 0xD3, 0x8D, 0x49, 0xA1, 0x0F, 0xE4, 0x9A, 0x50, 0xFA,
		0x16, 0x78, 0xBF, 0x32, 0xC4, 0x6D, 0x27, 0xD9, 0x93, 0x45, 0xAB, 0x07, 0xEE, 0x74, 0xBA, 0x4C,
		0x02, 0xFD, 0x68, 0x21, 0xD5, 0x8B, 0x3D, 0x97, 0x53, 0xC8, 0x0F, 0x86, 0x39, 0xFE, 0x60, 0x1A,
		0xAC, 0x55, 0xE3, 0x28, 0xCF, 0x74, 0xB8, 0x43, 0xF1, 0x0B, 0x9D, 0x47, 0xE8, 0x7F, 0x31, 0xC4,
		0x58, 0xF6, 0x1E, 0xB0, 0x65, 0x2C, 0xD1, 0x8F, 0x4B, 0xA3, 0x0D, 0xE2, 0x98, 0x52, 0xF8, 0x14,
		0x7A, 0xBD, 0x30, 0xC6, 0x6F, 0x25, 0xDB, 0x91, 0x43, 0xA9, 0x05, 0xEC, 0x72, 0xB8, 0x4E, 0x00,
		0xFF, 0x6A, 0x23, 0xD7, 0x89, 0x3F, 0x95, 0x51, 0xCA, 0x0D, 0x84, 0x3B, 0xFC, 0x62, 0x18, 0xAE,
		0x57, 0xE1, 0x2A, 0xCD, 0x76, 0xBA, 0x41, 0xF3, 0x09, 0x9F, 0x45, 0xEA, 0x7D, 0x33, 0xC6, 0x5A,
		0xF4, 0x1C, 0xB2, 0x67, 0x2E, 0xD3, 0x8D, 0x49, 0xA1, 0x0F, 0xE4, 0x9A, 0x50, 0xFA, 0x16, 0x78,
		0xBF, 0x32, 0xC4, 0x6D, 0x27, 0xD9, 0x93, 0x45, 0xAB, 0x07, 0xEE, 0x74, 0xBA, 0x4C, 0x02, 0xFD,
		0x68, 0x21, 0xD5, 0x8B, 0x3D, 0x97, 0x53, 0xC8, 0x0F, 0x86, 0x39, 0xFE, 0x60, 0x1A, 0xAC, 0x55,
		0xE3, 0x28, 0xCF, 0x74, 0xB8, 0x43, 0xF1, 0x0B, 0x9D, 0x47,0x7F, 0x81, 0x3A, 0xC2, 0x5D, 0xF0, 0x1E, 0xB4, 0x69, 0x2C, 0xD5, 0x8F, 0x47, 0xA3, 0x0B, 0xE6,
		0x9C, 0x52, 0xF8, 0x14, 0x7A, 0xBD, 0x30, 0xC8, 0x6F, 0x25, 0xDB, 0x91, 0x43, 0xA9, 0x05, 0xEC,
		0x72, 0xB8, 0x4E, 0x00, 0xFF, 0x6A, 0x23, 0xD7, 0x89, 0x3F, 0x95, 0x51, 0xCA, 0x0D, 0x84, 0x3B,
		0xFC, 0x62, 0x18, 0xAE, 0x57, 0xE1, 0x2A, 0xCD, 0x76, 0xBA, 0x41, 0xF3, 0x09, 0x9F, 0x45, 0xEA,
		0x7D, 0x33, 0xC6, 0x5A, 0xF4, 0x1C, 0xB2, 0x67, 0x2E, 0xD3, 0x8D, 0x49, 0xA1, 0x0F, 0xE4, 0x9A,
		0x50, 0xFA, 0x16, 0x78, 0xBF, 0x32, 0xC4, 0x6D, 0x27, 0xD9, 0x93, 0x45, 0xAB, 0x07, 0xEE, 0x74,
		0xBA, 0x4C, 0x02, 0xFD, 0x68, 0x21, 0xD5, 0x8B, 0x3D, 0x97, 0x53, 0xC8, 0x0F, 0x86, 0x39, 0xFE,
		0x60, 0x1A, 0xAC, 0x55, 0xE3, 0x28, 0xCF, 0x74, 0xB8, 0x43, 0xF1, 0x0B, 0x9D, 0x47, 0xE8, 0x7F,
		0x31, 0xC4, 0x58, 0xF6, 0x1E, 0xB0, 0x65, 0x2C, 0xD1, 0x8F, 0x4B, 0xA3, 0x0D, 0xE2, 0x98, 0x52,
		0xF8, 0x14, 0x7A, 0xBD, 0x30, 0xC6, 0x6F, 0x25, 0xDB, 0x91, 0x43, 0xA9, 0x05, 0xEC, 0x72, 0xB8,
		0x4E, 0x00, 0xFF, 0x6A, 0x23, 0xD7, 0x89, 0x3F, 0x95, 0x51, 0xCA, 0x0D, 0x84, 0x3B, 0xFC, 0x62,
		0x18, 0xAE, 0x57, 0xE1, 0x2A, 0xCD, 0x76, 0xBA, 0x41, 0xF3, 0x09, 0x9F, 0x45, 0xEA, 0x7D, 0x33,
		0xC6, 0x5A, 0xF4, 0x1C, 0xB2, 0x67, 0x2E, 0xD3, 0x8D, 0x49, 0xA1, 0x0F, 0xE4, 0x9A, 0x50, 0xFA,
		0x16, 0x78, 0xBF, 0x32, 0xC4, 0x6D, 0x27, 0xD9, 0x93, 0x45, 0xAB, 0x07, 0xEE, 0x74, 0xBA, 0x4C,
		0x02, 0xFD, 0x68, 0x21, 0xD5, 0x8B, 0x3D, 0x97, 0x53, 0xC8, 0x0F, 0x86, 0x39, 0xFE, 0x60, 0x1A,
		0xAC, 0x55, 0xE3, 0x28, 0xCF, 0x74, 0xB8, 0x43, 0xF1, 0x0B, 0x9D, 0x47, 0xE8, 0x7F, 0x31, 0xC4,
		0x58, 0xF6, 0x1E, 0xB0, 0x65, 0x2C, 0xD1, 0x8F, 0x4B, 0xA3, 0x0D, 0xE2, 0x98, 0x52, 0xF8, 0x14,
		0x7A, 0xBD, 0x30, 0xC6, 0x6F, 0x25, 0xDB, 0x91, 0x43, 0xA9, 0x05, 0xEC, 0x72, 0xB8, 0x4E, 0x00,
		0xFF, 0x6A, 0x23, 0xD7, 0x89, 0x3F, 0x95, 0x51, 0xCA, 0x0D, 0x84, 0x3B, 0xFC, 0x62, 0x18, 0xAE,
		0x57, 0xE1, 0x2A, 0xCD, 0x76, 0xBA, 0x41, 0xF3, 0x09, 0x9F, 0x45, 0xEA, 0x7D, 0x33, 0xC6, 0x5A,
		0xF4, 0x1C, 0xB2, 0x67, 0x2E, 0xD3, 0x8D, 0x49, 0xA1, 0x0F, 0xE4, 0x9A, 0x50, 0xFA, 0x16, 0x78,
		0xBF, 0x32, 0xC4, 0x6D, 0x27, 0xD9, 0x93, 0x45, 0xAB, 0x07, 0xEE, 0x74, 0xBA, 0x4C, 0x02, 0xFD,
		0x68, 0x21, 0xD5, 0x8B, 0x3D, 0x97, 0x53, 0xC8, 0x0F, 0x86, 0x39, 0xFE, 0x60, 0x1A, 0xAC, 0x55,
		0xE3, 0x28, 0xCF, 0x74, 0xB8, 0x43, 0xF1, 0x0B, 0x9D, 0x47,0x7F, 0x81, 0x3A, 0xC2, 0x5D, 0xF0, 0x1E, 0xB4, 0x69, 0x2C, 0xD5, 0x8F, 0x47, 0xA3, 0x0B, 0xE6,
		0x9C, 0x52, 0xF8, 0x14, 0x7A, 0xBD, 0x30, 0xC8, 0x6F, 0x25, 0xDB, 0x91, 0x43, 0xA9, 0x05, 0xEC,
		0x72, 0xB8, 0x4E, 0x00, 0xFF, 0x6A, 0x23, 0xD7, 0x89, 0x3F, 0x95, 0x51, 0xCA, 0x0D, 0x84, 0x3B,
		0xFC, 0x62, 0x18, 0xAE, 0x57, 0xE1, 0x2A, 0xCD, 0x76, 0xBA, 0x41, 0xF3, 0x09, 0x9F, 0x45, 0xEA,
		0x7D, 0x33, 0xC6, 0x5A, 0xF4, 0x1C, 0xB2, 0x67, 0x2E, 0xD3, 0x8D, 0x49, 0xA1, 0x0F, 0xE4, 0x9A,
		0x50, 0xFA, 0x16, 0x78, 0xBF, 0x32, 0xC4, 0x6D, 0x27, 0xD9, 0x93, 0x45, 0xAB, 0x07, 0xEE, 0x74,
		0xBA, 0x4C, 0x02, 0xFD, 0x68, 0x21, 0xD5, 0x8B, 0x3D, 0x97, 0x53, 0xC8, 0x0F, 0x86, 0x39, 0xFE,
		0x60, 0x1A, 0xAC, 0x55, 0xE3, 0x28, 0xCF, 0x74, 0xB8, 0x43, 0xF1, 0x0B, 0x9D, 0x47, 0xE8, 0x7F,
		0x31, 0xC4, 0x58, 0xF6, 0x1E, 0xB0, 0x65, 0x2C, 0xD1, 0x8F, 0x4B, 0xA3, 0x0D, 0xE2, 0x98, 0x52,
		0xF8, 0x14, 0x7A, 0xBD, 0x30, 0xC6, 0x6F, 0x25, 0xDB, 0x91, 0x43, 0xA9, 0x05, 0xEC, 0x72, 0xB8,
		0x4E, 0x00, 0xFF, 0x6A, 0x23, 0xD7, 0x89, 0x3F, 0x95, 0x51, 0xCA, 0x0D, 0x84, 0x3B, 0xFC, 0x62,
		0x18, 0xAE, 0x57, 0xE1, 0x2A, 0xCD, 0x76, 0xBA, 0x41, 0xF3, 0x09, 0x9F, 0x45, 0xEA, 0x7D, 0x33,
		0xC6, 0x5A, 0xF4, 0x1C, 0xB2, 0x67, 0x2E, 0xD3, 0x8D, 0x49, 0xA1, 0x0F, 0xE4, 0x9A, 0x50, 0xFA,
		0x16, 0x78, 0xBF, 0x32, 0xC4, 0x6D, 0x27, 0xD9, 0x93, 0x45, 0xAB, 0x07, 0xEE, 0x74, 0xBA, 0x4C,
		0x02, 0xFD, 0x68, 0x21, 0xD5, 0x8B, 0x3D, 0x97, 0x53, 0xC8, 0x0F, 0x86, 0x39, 0xFE, 0x60, 0x1A,
		0xAC, 0x55, 0xE3, 0x28, 0xCF, 0x74, 0xB8, 0x43, 0xF1, 0x0B, 0x9D, 0x47, 0xE8, 0x7F, 0x31, 0xC4,
		0x58, 0xF6, 0x1E, 0xB0, 0x65, 0x2C, 0xD1, 0x8F, 0x4B, 0xA3, 0x0D, 0xE2, 0x98, 0x52, 0xF8, 0x14,
		0x7A, 0xBD, 0x30, 0xC6, 0x6F, 0x25, 0xDB, 0x91, 0x43, 0xA9, 0x05, 0xEC, 0x72, 0xB8, 0x4E, 0x00,
		0xFF, 0x6A, 0x23, 0xD7, 0x89, 0x3F, 0x95, 0x51, 0xCA, 0x0D, 0x84, 0x3B, 0xFC, 0x62, 0x18, 0xAE,
		0x57, 0xE1, 0x2A, 0xCD, 0x76, 0xBA, 0x41, 0xF3, 0x09, 0x9F, 0x45, 0xEA, 0x7D, 0x33, 0xC6, 0x5A,
		0xF4, 0x1C, 0xB2, 0x67, 0x2E, 0xD3, 0x8D, 0x49, 0xA1, 0x0F, 0xE4, 0x9A, 0x50, 0xFA, 0x16, 0x78,
		0xBF, 0x32, 0xC4, 0x6D, 0x27, 0xD9, 0x93, 0x45, 0xAB, 0x07, 0xEE, 0x74, 0xBA, 0x4C, 0x02, 0xFD,
		0x68, 0x21, 0xD5, 0x8B, 0x3D, 0x97, 0x53, 0xC8, 0x0F, 0x86, 0x39, 0xFE, 0x60, 0x1A, 0xAC, 0x55,
		0xE3, 0x28, 0xCF, 0x74, 0xB8, 0x43, 0xF1, 0x0B, 0x9D, 0x47};

/* USER CODE END 0 */

int main(void) {

	/* MCU Configuration--------------------------------------------------------*/

	/* Reset of all peripherals, Initializes the Flash interface and the Systick. */
	HAL_Init();

	/* Configure the system clock */
	SystemClock_Config();

	/* Initialize all configured peripherals */
	MX_GPIO_Init();
	MX_USART2_UART_Init();
	MX_SPI2_Init();
	/* USER CODE BEGIN 2 */
	vs1003_begin();
	vs1003_setVolume(0x00);

	//trying inverting audio
	uint16_t mask = 0;
	mask |= 0b1 << 0;
	vs1003_write_register(0x00, vs1003_read_register(0x00) | mask);

	vs1003_print_all_register_details();
	/* USER CODE END 2 */

	/* Infinite loop */
	while (1) {

		/* USER CODE BEGIN 3 */
		vs1003_playChunk(pcm_data, sizeof(pcm_data));
		vs1003_print_all_register_details();
		HAL_GPIO_TogglePin(LED_GREEN_GPIO_Port, LED_GREEN_Pin);
		HAL_Delay(100);
	}
	/* USER CODE END 3 */
}

void SystemClock_Config(void) {
	RCC_OscInitTypeDef RCC_OscInitStruct = { 0 };
	RCC_ClkInitTypeDef RCC_ClkInitStruct = { 0 };

	/** Configure the main internal regulator output voltage
	 */
	__HAL_RCC_PWR_CLK_ENABLE();
	__HAL_PWR_VOLTAGESCALING_CONFIG(PWR_REGULATOR_VOLTAGE_SCALE1);

	/** Initializes the RCC Oscillators according to the specified parameters
	 * in the RCC_OscInitTypeDef structure.
	 */
	RCC_OscInitStruct.OscillatorType = RCC_OSCILLATORTYPE_HSI;
	RCC_OscInitStruct.HSIState = RCC_HSI_ON;
	RCC_OscInitStruct.HSICalibrationValue = RCC_HSICALIBRATION_DEFAULT;
	RCC_OscInitStruct.PLL.PLLState = RCC_PLL_ON;
	RCC_OscInitStruct.PLL.PLLSource = RCC_PLLSOURCE_HSI;
	RCC_OscInitStruct.PLL.PLLM = 16;
	RCC_OscInitStruct.PLL.PLLN = 336;
	RCC_OscInitStruct.PLL.PLLP = RCC_PLLP_DIV4;
	RCC_OscInitStruct.PLL.PLLQ = 4;
	RCC_OscInitStruct.PLL.PLLR = 2;
	if (HAL_RCC_OscConfig(&RCC_OscInitStruct) != HAL_OK) {
		Error_Handler();
	}

	/** Initializes the CPU, AHB and APB buses clocks
	 */
	RCC_ClkInitStruct.ClockType = RCC_CLOCKTYPE_HCLK | RCC_CLOCKTYPE_SYSCLK
			| RCC_CLOCKTYPE_PCLK1 | RCC_CLOCKTYPE_PCLK2;
	RCC_ClkInitStruct.SYSCLKSource = RCC_SYSCLKSOURCE_PLLCLK;
	RCC_ClkInitStruct.AHBCLKDivider = RCC_SYSCLK_DIV1;
	RCC_ClkInitStruct.APB1CLKDivider = RCC_HCLK_DIV2;
	RCC_ClkInitStruct.APB2CLKDivider = RCC_HCLK_DIV1;

	if (HAL_RCC_ClockConfig(&RCC_ClkInitStruct, FLASH_LATENCY_2) != HAL_OK) {
		Error_Handler();
	}
}

static void MX_SPI2_Init(void) {

	/* SPI2 parameter configuration*/
	hspi2.Instance = SPI2;
	hspi2.Init.Mode = SPI_MODE_MASTER;
	hspi2.Init.Direction = SPI_DIRECTION_2LINES;
	hspi2.Init.DataSize = SPI_DATASIZE_8BIT;
	hspi2.Init.CLKPolarity = SPI_POLARITY_LOW;
	hspi2.Init.CLKPhase = SPI_PHASE_1EDGE;
	hspi2.Init.NSS = SPI_NSS_SOFT;
	hspi2.Init.BaudRatePrescaler = SPI_BAUDRATEPRESCALER_16;
	hspi2.Init.FirstBit = SPI_FIRSTBIT_MSB;
	hspi2.Init.TIMode = SPI_TIMODE_DISABLE;
	hspi2.Init.CRCCalculation = SPI_CRCCALCULATION_DISABLE;
	hspi2.Init.CRCPolynomial = 15;
	if (HAL_SPI_Init(&hspi2) != HAL_OK) {
		Error_Handler();
	}

}

static void MX_USART2_UART_Init(void) {

	huart2.Instance = USART2;
	huart2.Init.BaudRate = 115200;
	huart2.Init.WordLength = UART_WORDLENGTH_8B;
	huart2.Init.StopBits = UART_STOPBITS_1;
	huart2.Init.Parity = UART_PARITY_NONE;
	huart2.Init.Mode = UART_MODE_TX_RX;
	huart2.Init.HwFlowCtl = UART_HWCONTROL_NONE;
	huart2.Init.OverSampling = UART_OVERSAMPLING_16;
	if (HAL_UART_Init(&huart2) != HAL_OK) {
		Error_Handler();
	}

}

static void MX_GPIO_Init(void) {
	GPIO_InitTypeDef GPIO_InitStruct = { 0 };

	/* GPIO Ports Clock Enable */
	__HAL_RCC_GPIOC_CLK_ENABLE();
	__HAL_RCC_GPIOH_CLK_ENABLE();
	__HAL_RCC_GPIOA_CLK_ENABLE();
	__HAL_RCC_GPIOB_CLK_ENABLE();

	/*Configure GPIO pin Output Level */
	HAL_GPIO_WritePin(DCS_GPIO_Port, DCS_Pin, GPIO_PIN_RESET);

	/*Configure GPIO pin Output Level */
	HAL_GPIO_WritePin(LED_GREEN_GPIO_Port, LED_GREEN_Pin, GPIO_PIN_RESET);

	/*Configure GPIO pin Output Level */
	HAL_GPIO_WritePin(GPIOB, RST_Pin | CS_Pin, GPIO_PIN_RESET);

	/*Configure GPIO pin : B1_Pin */
	GPIO_InitStruct.Pin = B1_Pin;
	GPIO_InitStruct.Mode = GPIO_MODE_IT_FALLING;
	GPIO_InitStruct.Pull = GPIO_NOPULL;
	HAL_GPIO_Init(B1_GPIO_Port, &GPIO_InitStruct);

	/*Configure GPIO pin : DCS_Pin */
	GPIO_InitStruct.Pin = DCS_Pin;
	GPIO_InitStruct.Mode = GPIO_MODE_OUTPUT_PP;
	GPIO_InitStruct.Pull = GPIO_NOPULL;
	GPIO_InitStruct.Speed = GPIO_SPEED_FREQ_LOW;
	HAL_GPIO_Init(DCS_GPIO_Port, &GPIO_InitStruct);

	/*Configure GPIO pin : DREQ_Pin */
	GPIO_InitStruct.Pin = DREQ_Pin;
	GPIO_InitStruct.Mode = GPIO_MODE_INPUT;
	GPIO_InitStruct.Pull = GPIO_NOPULL;
	HAL_GPIO_Init(DREQ_GPIO_Port, &GPIO_InitStruct);

	/*Configure GPIO pin : LED_GREEN_Pin */
	GPIO_InitStruct.Pin = LED_GREEN_Pin;
	GPIO_InitStruct.Mode = GPIO_MODE_OUTPUT_PP;
	GPIO_InitStruct.Pull = GPIO_NOPULL;
	GPIO_InitStruct.Speed = GPIO_SPEED_FREQ_LOW;
	HAL_GPIO_Init(LED_GREEN_GPIO_Port, &GPIO_InitStruct);

	/*Configure GPIO pins : RST_Pin CS_Pin */
	GPIO_InitStruct.Pin = RST_Pin | CS_Pin;
	GPIO_InitStruct.Mode = GPIO_MODE_OUTPUT_PP;
	GPIO_InitStruct.Pull = GPIO_NOPULL;
	GPIO_InitStruct.Speed = GPIO_SPEED_FREQ_LOW;
	HAL_GPIO_Init(GPIOB, &GPIO_InitStruct);

}

void Error_Handler(void) {
	__disable_irq();
	while (1) {
	}
}
